VERSION ""

NS_ :

BS_:

BU_: APU BCU DCH DCL MCU TMS VIU WBS VIU1

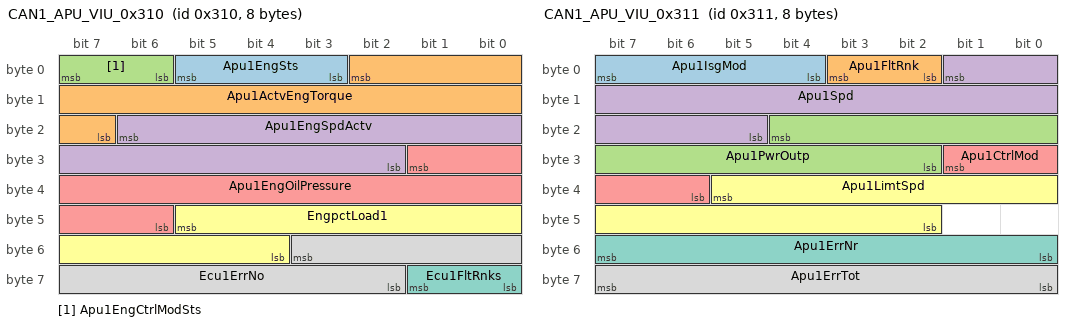
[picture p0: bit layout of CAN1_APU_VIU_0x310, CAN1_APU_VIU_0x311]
BO_ 784 CAN1_APU_VIU_0x310: 8 APU
 SG_ Apu1EngSts : 5|3@0+ (1,0) [0|7] ""  VIU
 SG_ Apu1ActvEngTorque : 2|12@0+ (1,-1250) [-1250|1250] "Nm"  VIU
 SG_ Apu1EngCtrlModSts : 7|2@0+ (1,0) [0|3] ""  VIU
 SG_ Apu1EngSpdActv : 22|13@0+ (1,0) [0|8000] "rpm"  VIU
 SG_ Apu1EngOilPressure : 25|12@0+ (0.055,0) [0|220] "mPa"  VIU
 SG_ EngpctLoad1 : 45|10@0+ (0.1,0) [0|100] "%"  VIU
 SG_ Ecu1FltRnks : 57|2@0+ (1,0) [0|3] ""  VIU
 SG_ Ecu1ErrNo : 51|10@0+ (1,0) [0|1000] ""  VIU

BO_ 785 CAN1_APU_VIU_0x311: 8 APU
 SG_ Apu1IsgMod : 7|4@0+ (1,0) [0|15] ""  VIU
 SG_ Apu1FltRnk : 3|2@0+ (1,0) [0|3] ""  VIU
 SG_ Apu1PwrOutp : 20|11@0+ (0.1,-150) [-150|50] "kW"  VIU
 SG_ Apu1Spd : 1|13@0+ (5,-15000) [-15000|15000] "rpm"  VIU
 SG_ Apu1CtrlMod : 25|4@0+ (1,0) [0|15] ""  VIU
 SG_ Apu1LimtSpd : 37|12@0+ (5,-8000) [-8000|8000] "rpm"  VIU
 SG_ Apu1ErrNr : 55|8@0+ (1,0) [0|255] ""  VIU
 SG_ Apu1ErrTot : 63|8@0+ (1,0) [0|255] ""  VIU

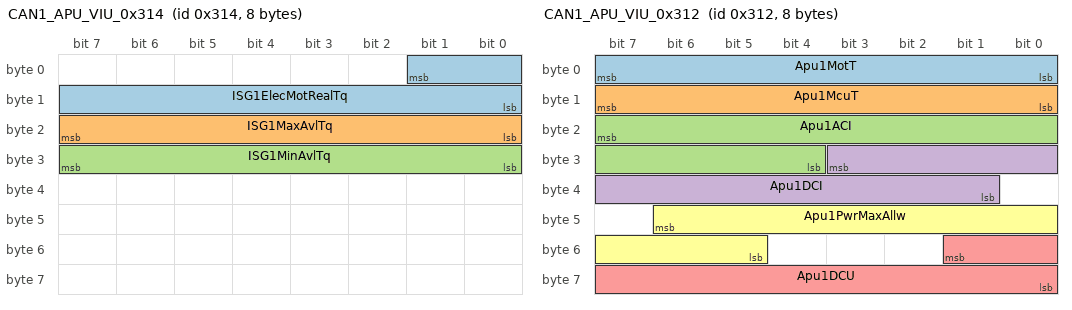
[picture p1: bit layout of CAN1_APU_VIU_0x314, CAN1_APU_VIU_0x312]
BO_ 788 CAN1_APU_VIU_0x314: 8 APU
 SG_ ISG1ElecMotRealTq : 1|10@0+ (1,-250) [-250|250] "Nm"  VIU
 SG_ ISG1MaxAvlTq : 23|8@0+ (1,0) [0|250] "Nm"  VIU
 SG_ ISG1MinAvlTq : 31|8@0+ (1,-250) [-250|0] "Nm"  VIU

BO_ 786 CAN1_APU_VIU_0x312: 8 APU
 SG_ Apu1MotT : 7|8@0+ (1,-50) [-50|200] "℃"  VIU
 SG_ Apu1McuT : 15|8@0+ (1,-50) [-50|200] "℃"  VIU
 SG_ Apu1ACI : 23|12@0+ (1,0) [0|1500] "A"  VIU
 SG_ Apu1DCI : 27|11@0+ (1,-1000) [-1000|1000] "A"  VIU
 SG_ Apu1DCU : 49|10@0+ (1,0) [0|1000] "V"  VIU
 SG_ Apu1PwrMaxAllw : 46|10@0+ (1,0) [0|1000] "kW"  VIU

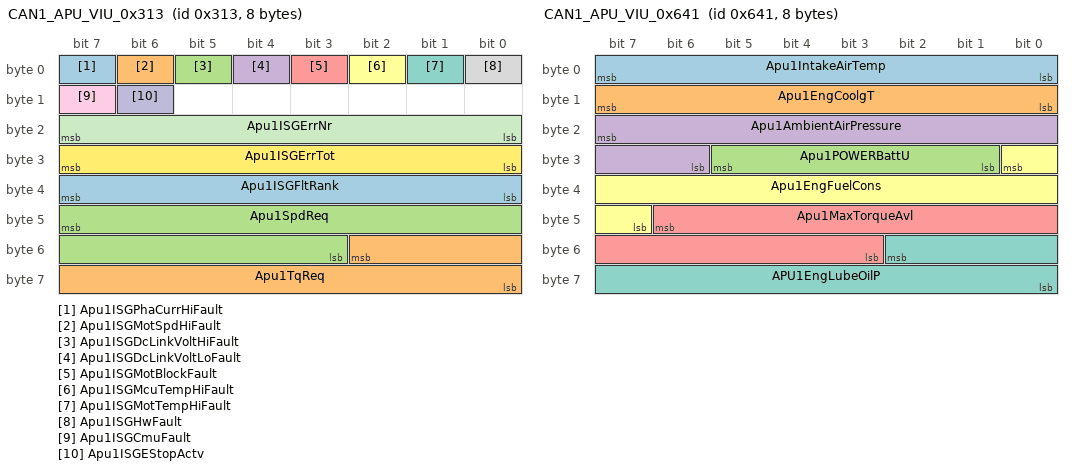
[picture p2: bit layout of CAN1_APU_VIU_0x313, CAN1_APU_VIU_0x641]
BO_ 787 CAN1_APU_VIU_0x313: 8 APU
 SG_ Apu1ISGPhaCurrHiFault : 7|1@0+ (1,0) [0|1] ""  VIU
 SG_ Apu1ISGMotSpdHiFault : 6|1@0+ (1,0) [0|1] ""  VIU
 SG_ Apu1ISGDcLinkVoltHiFault : 5|1@0+ (1,0) [0|1] ""  VIU
 SG_ Apu1ISGDcLinkVoltLoFault : 4|1@0+ (1,0) [0|1] ""  VIU
 SG_ Apu1ISGMotBlockFault : 3|1@0+ (1,0) [0|1] ""  VIU
 SG_ Apu1ISGMcuTempHiFault : 2|1@0+ (1,0) [0|1] ""  VIU
 SG_ Apu1ISGMotTempHiFault : 1|1@0+ (1,0) [0|1] ""  VIU
 SG_ Apu1ISGHwFault : 0|1@0+ (1,0) [0|1] ""  VIU
 SG_ Apu1ISGCmuFault : 15|1@0+ (1,0) [0|1] ""  VIU
 SG_ Apu1ISGEStopActv : 14|1@0+ (1,0) [0|1] ""  VIU
 SG_ Apu1ISGErrNr : 23|8@0+ (1,0) [0|255] ""  VIU
 SG_ Apu1ISGErrTot : 31|8@0+ (1,0) [0|255] ""  VIU
 SG_ Apu1ISGFltRank : 39|8@0+ (1,0) [0|255] ""  VIU
 SG_ Apu1TqReq : 50|11@0+ (0.5,-500) [-500|500] "Nm"  VIU
 SG_ Apu1SpdReq : 47|13@0+ (5,0) [0|10000] "rpm"  VIU

BO_ 1601 CAN1_APU_VIU_0x641: 8 APU
 SG_ Apu1IntakeAirTemp : 7|8@0+ (1,-40) [-40|210] "℃"  VIU
 SG_ Apu1EngCoolgT : 15|8@0+ (1,-40) [-40|210] "℃"  VIU
 SG_ Apu1POWERBattU : 29|5@0+ (1,0) [0|30] "V"  VIU
 SG_ Apu1AmbientAirPressure : 23|10@0+ (1,0) [0|1000] "kPa"  VIU
 SG_ Apu1MaxTorqueAvl : 46|12@0+ (1,-1250) [-1250|1250] "Nm"  VIU
 SG_ Apu1EngFuelCons : 24|10@0+ (0.05,0) [0|51] "mL"  VIU
 SG_ APU1EngLubeOilP : 50|11@0+ (1,0) [0|1000] "kPa"  VIU

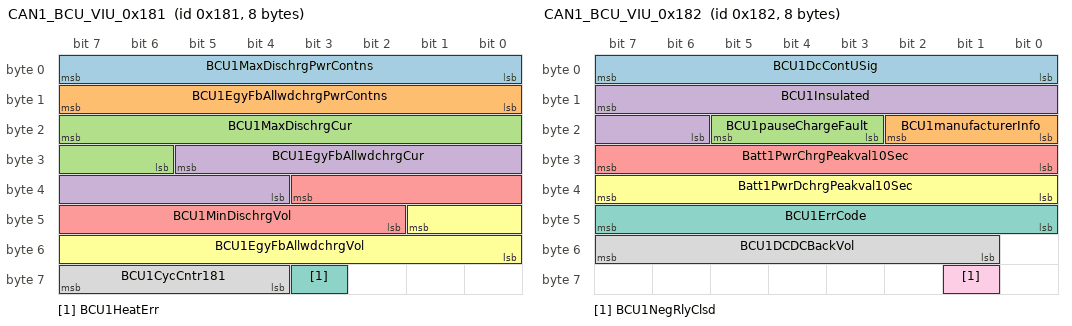
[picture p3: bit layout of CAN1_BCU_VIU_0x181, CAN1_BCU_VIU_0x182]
BO_ 385 CAN1_BCU_VIU_0x181: 8 BCU
 SG_ BCU1MaxDischrgPwrContns : 7|8@0+ (0.5,0) [0|125] "kW"  VIU
 SG_ BCU1EgyFbAllwdchrgPwrContns : 15|8@0+ (0.5,0) [0|125] "kW"  VIU
 SG_ BCU1MaxDischrgCur : 23|10@0+ (1,0) [0|500] "kW"  VIU
 SG_ BCU1EgyFbAllwdchrgCur : 29|10@0+ (1,0) [0|500] "A"  VIU
 SG_ BCU1MinDischrgVol : 35|10@0+ (1,0) [0|800] "V"  VIU
 SG_ BCU1EgyFbAllwdchrgVol : 41|10@0+ (1,0) [0|800] "V"  VIU
 SG_ BCU1HeatErr : 59|1@0+ (1,0) [0|1] ""  VIU
 SG_ BCU1CycCntr181 : 63|4@0+ (1,0) [0|15] "V"  VIU

BO_ 386 CAN1_BCU_VIU_0x182: 8 BCU
 SG_ BCU1DcContUSig : 7|8@0+ (0.1,0) [0|20] "V"  VIU
 SG_ BCU1manufacturerInfo : 18|3@0+ (1,0) [0|7] ""  VIU
 SG_ BCU1pauseChargeFault : 21|3@0+ (1,0) [0|7] ""  VIU
 SG_ BCU1Insulated : 15|10@0+ (1,0) [0|1000] "kΩ"  VIU
 SG_ Batt1PwrChrgPeakval10Sec : 31|8@0+ (0.5,0) [0|125] "kW"  VIU
 SG_ Batt1PwrDchrgPeakval10Sec : 39|8@0+ (0.5,0) [0|125] "kW"  VIU
 SG_ BCU1ErrCode : 47|8@0+ (1,0) [0|255] ""  VIU
 SG_ BCU1DCDCBackVol : 55|7@0+ (5,0) [0|635] "V"  VIU
 SG_ BCU1NegRlyClsd : 57|1@0+ (1,0) [0|1] ""  VIU

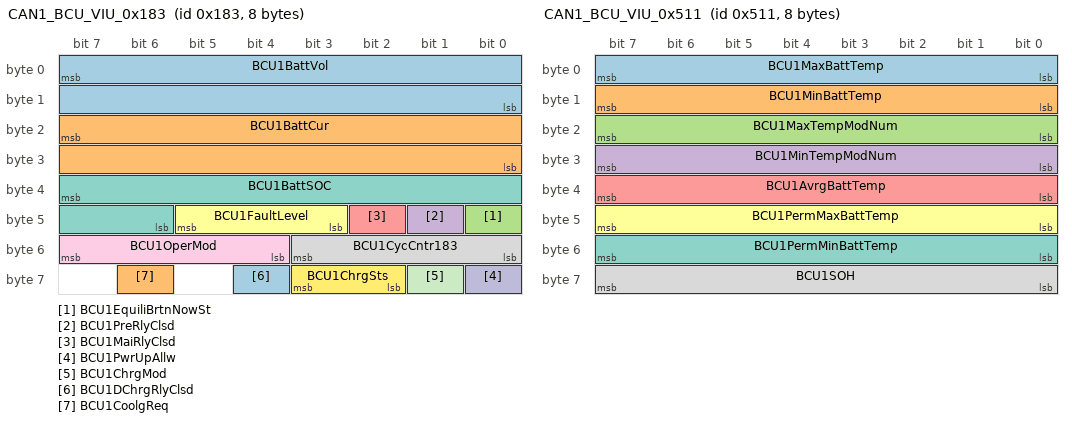
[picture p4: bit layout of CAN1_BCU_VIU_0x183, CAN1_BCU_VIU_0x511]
BO_ 387 CAN1_BCU_VIU_0x183: 8 BCU
 SG_ BCU1BattVol : 7|16@0+ (0.1,0) [0|800] "V"  VIU
 SG_ BCU1BattCur : 23|16@0+ (0.1,-500) [-500|500] "A"  VIU
 SG_ BCU1EquiliBrtnNowSt : 40|1@0+ (1,0) [0|1] ""  VIU
 SG_ BCU1PreRlyClsd : 41|1@0+ (1,0) [0|1] ""  VIU
 SG_ BCU1MaiRlyClsd : 42|1@0+ (1,0) [0|1] ""  VIU
 SG_ BCU1FaultLevel : 45|3@0+ (1,0) [0|4] ""  VIU
 SG_ BCU1BattSOC : 39|10@0+ (0.1,0) [0|100] "%"  VIU
 SG_ BCU1CycCntr183 : 51|4@0+ (1,0) [0|15] ""  VIU
 SG_ BCU1OperMod : 55|4@0+ (1,0) [0|15] ""  VIU
 SG_ BCU1PwrUpAllw : 56|1@0+ (1,0) [0|1] ""  VIU
 SG_ BCU1ChrgMod : 57|1@0+ (1,0) [0|1] ""  VIU
 SG_ BCU1ChrgSts : 59|2@0+ (1,0) [0|3] ""  VIU
 SG_ BCU1DChrgRlyClsd : 60|1@0+ (1,0) [0|1] ""  VIU
 SG_ BCU1CoolgReq : 62|1@0+ (1,0) [0|1] ""  VIU

BO_ 1297 CAN1_BCU_VIU_0x511: 8 BCU
 SG_ BCU1MaxBattTemp : 7|8@0+ (1,-40) [-40|125] "℃"  VIU
 SG_ BCU1MinBattTemp : 15|8@0+ (1,-40) [-40|125] "℃"  VIU
 SG_ BCU1MaxTempModNum : 23|8@0+ (1,0) [1|120] ""  VIU
 SG_ BCU1MinTempModNum : 31|8@0+ (1,0) [1|120] ""  VIU
 SG_ BCU1AvrgBattTemp : 39|8@0+ (1,-40) [-40|125] "℃"  VIU
 SG_ BCU1PermMaxBattTemp : 47|8@0+ (1,-40) [-40|125] "℃"  VIU
 SG_ BCU1PermMinBattTemp : 55|8@0+ (1,-40) [-40|125] "℃"  VIU
 SG_ BCU1SOH : 63|8@0+ (1,0) [0|100] "%"  VIU

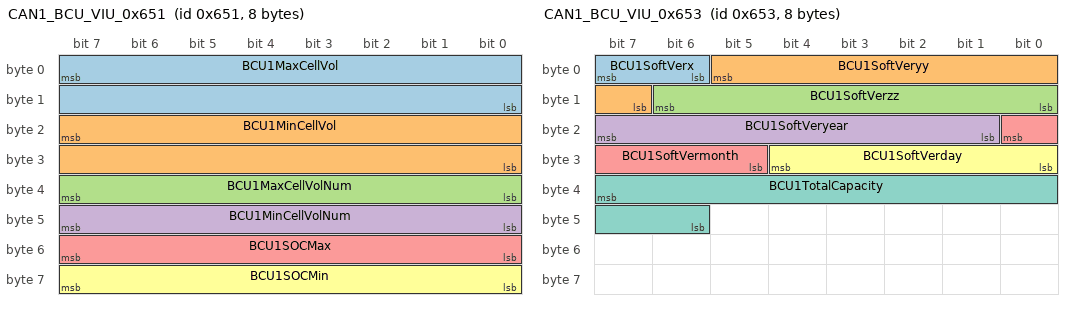
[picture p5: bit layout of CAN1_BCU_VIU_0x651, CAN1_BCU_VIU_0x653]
BO_ 1617 CAN1_BCU_VIU_0x651: 8 BCU
 SG_ BCU1MaxCellVol : 7|16@0+ (0.001,0) [0|10.001] "V"  VIU
 SG_ BCU1MinCellVol : 23|16@0+ (0.001,0) [0|10.001] "V"  VIU
 SG_ BCU1MaxCellVolNum : 39|8@0+ (1,0) [1|110] ""  VIU
 SG_ BCU1MinCellVolNum : 47|8@0+ (1,0) [1|110] ""  VIU
 SG_ BCU1SOCMax : 55|8@0+ (1,0) [0|100] "%"  VIU
 SG_ BCU1SOCMin : 63|8@0+ (1,0) [0|100] "%"  VIU

BO_ 1618 CAN1_BCU_VIU_0x652: 8 BCU
 SG_ BCU1CellDeltaVolRank2 : 0|1@0+ (1,0) [0|1] ""  VIU
 SG_ BCU1CellDeltaVolRank1 : 1|1@0+ (1,0) [0|1] ""  VIU
 SG_ BCU1CellUnderVolRank3 : 2|1@0+ (1,0) [0|1] ""  VIU
 SG_ BCU1CellUnderVolRank2 : 3|1@0+ (1,0) [0|1] ""  VIU
 SG_ BCU1CellUnderVolRank1 : 4|1@0+ (1,0) [0|1] ""  VIU
 SG_ BCU1CellOverVolRank3 : 5|1@0+ (1,0) [0|1] ""  VIU
 SG_ BCU1CellOverVolRank2 : 6|1@0+ (1,0) [0|1] ""  VIU
 SG_ BCU1CellOverVolRank1 : 7|1@0+ (1,0) [0|1] ""  VIU
 SG_ BCU1OverCurtChrgRank3 : 8|1@0+ (1,0) [0|1] ""  VIU
 SG_ BCU1OverCurtChrgRank2 : 9|1@0+ (1,0) [0|1] ""  VIU
 SG_ BCU1OverCurtChrgRank1 : 10|1@0+ (1,0) [0|1] ""  VIU
 SG_ BCU1PrechrgFailErr : 11|1@0+ (1,0) [0|1] ""  VIU
 SG_ BCU1DCRlyPAdhErr : 12|1@0+ (1,0) [0|1] ""  VIU
 SG_ BCU1MaiRlyPAdhErr : 13|1@0+ (1,0) [0|1] ""  VIU
 SG_ BCU1MaiRlyNAdhErr : 14|1@0+ (1,0) [0|1] ""  VIU
 SG_ BCU1CC2Err : 15|1@0+ (1,0) [0|1] ""  VIU
 SG_ BCU1OverPeakCurtDischrgRank2 : 16|1@0+ (1,0) [0|1] ""  VIU
 SG_ BCU1OverPeakCurtDischrgRank1 : 17|1@0+ (1,0) [0|1] ""  VIU
 SG_ BCU1OverCurtDischrgRank3 : 18|1@0+ (1,0) [0|1] ""  VIU
 SG_ BCU1OverCurtDischrgRank2 : 19|1@0+ (1,0) [0|1] ""  VIU
 SG_ BCU1OverCurtDischrgRank1 : 20|1@0+ (1,0) [0|1] ""  VIU
 SG_ BCU1OverPeakCurtChrgRank3 : 21|1@0+ (1,0) [0|1] ""  VIU
 SG_ BCU1OverPeakCurtChrgRank2 : 22|1@0+ (1,0) [0|1] ""  VIU
 SG_ BCU1OverPeakCurtChrgRank1 : 23|1@0+ (1,0) [0|1] ""  VIU
 SG_ BCU1BattUnderTempRank2 : 24|1@0+ (1,0) [0|1] ""  VIU
 SG_ BCU1BattOverTempRank4 : 25|1@0+ (1,0) [0|1] ""  VIU
 SG_ BCU1BattOverTempRank3 : 26|1@0+ (1,0) [0|1] ""  VIU
 SG_ BCU1BattOverTempRank2 : 27|1@0+ (1,0) [0|1] ""  VIU
 SG_ BCU1ChrgErr : 28|1@0+ (1,0) [0|1] ""  VIU
 SG_ BCU1BattSOHLo : 29|1@0+ (1,0) [0|1] ""  VIU
 SG_ BCU1TotVolRatiErr : 30|1@0+ (1,0) [0|1] ""  VIU
 SG_ BCU1OverPeakCurtDischrgRank3 : 31|1@0+ (1,0) [0|1] ""  VIU
 SG_ BCU1BattOverURank2 : 32|1@0+ (1,0) [0|1] ""  VIU
 SG_ BCU1BattOverVolRank1 : 33|1@0+ (1,0) [0|1] ""  VIU
 SG_ BCU1InsuFlt4 : 34|1@0+ (1,0) [0|1] ""  VIU
 SG_ BCU1InsuFlt2 : 35|1@0+ (1,0) [0|1] ""  VIU
 SG_ BCU1HVILErr : 36|1@0+ (1,0) [0|1] ""  VIU
 SG_ BCU1DeltaTempRank3 : 37|1@0+ (1,0) [0|1] ""  VIU
 SG_ BCU1DeltaTempRank2 : 38|1@0+ (1,0) [0|1] ""  VIU
 SG_ BCU1BattUnderTempRank3 : 39|1@0+ (1,0) [0|1] ""  VIU
 SG_ BCU1SOCHopErr : 40|1@0+ (1,0) [0|1] ""  VIU
 SG_ BCU1SOCcalcErr : 41|1@0+ (1,0) [0|1] ""  VIU
 SG_ BCU1BattOverPwr : 42|1@0+ (1,0) [0|1] ""  VIU
 SG_ BCU1DCchrgInsuFlt : 43|1@0+ (1,0) [0|1] ""  VIU
 SG_ BCU1BattUnderVolRank3 : 44|1@0+ (1,0) [0|1] ""  VIU
 SG_ BCU1BattUnderVolRank2 : 45|1@0+ (1,0) [0|1] ""  VIU
 SG_ BCU1BattUnderURank1 : 46|1@0+ (1,0) [0|1] ""  VIU
 SG_ BCU1BattOverURank3 : 47|1@0+ (1,0) [0|1] ""  VIU
 SG_ BCU1TotVolSnsrElecErr : 48|1@0+ (1,0) [0|1] ""  VIU
 SG_ BCU1SlaveCALFAULT : 49|1@0+ (1,0) [0|1] ""  VIU
 SG_ BCU1InlrCANErr : 50|1@0+ (1,0) [0|1] ""  VIU
 SG_ BCU1ChrgCANErr : 51|1@0+ (1,0) [0|1] ""  VIU
 SG_ BCU1VehCANErr : 52|1@0+ (1,0) [0|1] ""  VIU
 SG_ BCU1BlcErr : 53|1@0+ (1,0) [0|1] ""  VIU
 SG_ BCU1ChargerOverTemp3 : 54|1@0+ (1,0) [0|1] ""  VIU
 SG_ BCU1ChargerOverTemp2 : 55|1@0+ (1,0) [0|1] ""  VIU
 SG_ BCU1DCchrgTemErr : 57|1@0+ (1,0) [0|1] ""  VIU
 SG_ BCU1EEpErr : 58|1@0+ (1,0) [0|1] ""  VIU
 SG_ BCU1WatchDogErr : 59|1@0+ (1,0) [0|1] ""  VIU
 SG_ BCU1ROMCheckErr : 60|1@0+ (1,0) [0|1] ""  VIU
 SG_ BCU1RAMCheckErr : 61|1@0+ (1,0) [0|1] ""  VIU
 SG_ BCU1TempSnsrElecErr : 62|1@0+ (1,0) [0|1] ""  VIU
 SG_ BCU1TotCurtSnsrElecErr : 63|1@0+ (1,0) [0|1] ""  VIU

BO_ 1619 CAN1_BCU_VIU_0x653: 8 BCU
 SG_ BCU1SoftVerx : 7|2@0+ (1,0) [0|3] ""  VIU
 SG_ BCU1SoftVeryy : 5|7@0+ (1,0) [0|99] ""  VIU
 SG_ BCU1SoftVerzz : 14|7@0+ (1,0) [0|99] ""  VIU
 SG_ BCU1SoftVeryear : 23|7@0+ (1,2000) [2000|2099] ""  VIU
 SG_ BCU1SoftVermonth : 16|4@0+ (1,0) [1|12] ""  VIU
 SG_ BCU1SoftVerday : 28|5@0+ (1,0) [1|31] ""  VIU
 SG_ BCU1TotalCapacity : 39|10@0+ (0.1,0) [0|100] "Ah"  VIU

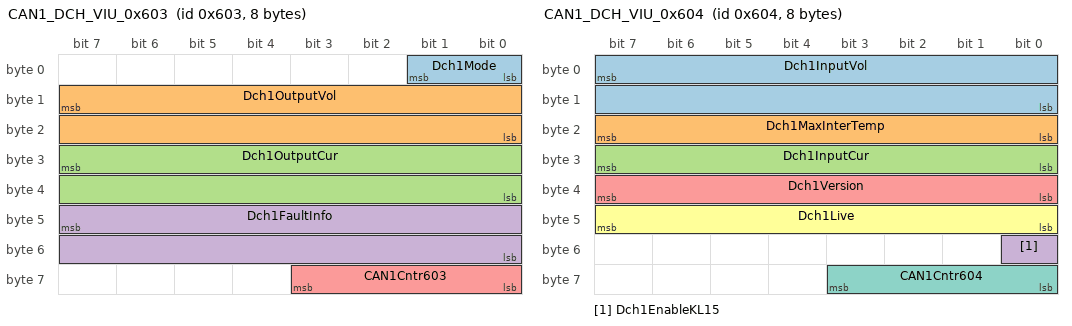
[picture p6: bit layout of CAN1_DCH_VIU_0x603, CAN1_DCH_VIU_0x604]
BO_ 1539 CAN1_DCH_VIU_0x603: 8 DCH
 SG_ Dch1Mode : 1|2@0+ (1,0) [0|3] ""  VIU
 SG_ Dch1OutputVol : 15|16@0+ (0.1,0) [0|6553.5] "V"  VIU
 SG_ Dch1OutputCur : 31|16@0+ (0.1,0) [0|6553.5] "A"  VIU
 SG_ Dch1FaultInfo : 47|16@0+ (1,0) [0|65535] ""  VIU
 SG_ CAN1Cntr603 : 59|4@0+ (1,0) [0|15] ""  VIU

BO_ 1540 CAN1_DCH_VIU_0x604: 8 DCH
 SG_ Dch1InputVol : 7|16@0+ (0.1,0) [0|6553.5] "V"  VIU
 SG_ Dch1MaxInterTemp : 23|8@0+ (1,-40) [-40|215] "℃"  VIU
 SG_ Dch1InputCur : 31|8@0+ (0.1,0) [0|25.5] "A"  VIU
 SG_ Dch1EnableKL15 : 48|1@0+ (1,0) [0|1] ""  VIU
 SG_ Dch1Version : 39|8@0+ (1,0) [0|255] ""  VIU
 SG_ Dch1Live : 47|8@0+ (1,0) [0|255] ""  VIU
 SG_ CAN1Cntr604 : 59|4@0+ (1,0) [0|15] ""  VIU

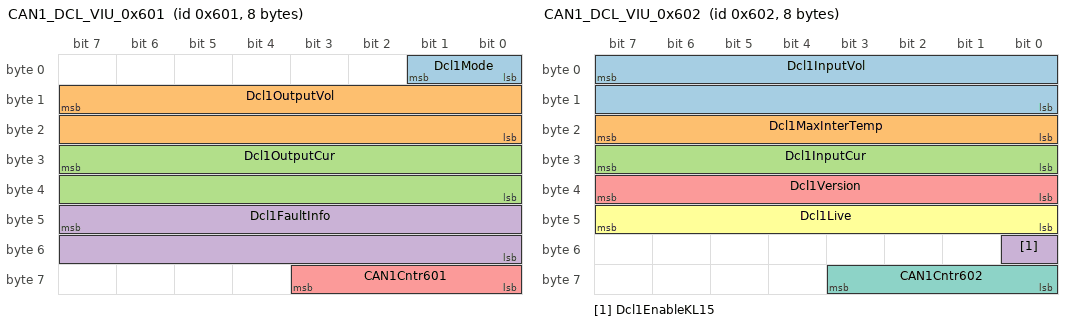
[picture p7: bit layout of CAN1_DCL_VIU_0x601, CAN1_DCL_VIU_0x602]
BO_ 1537 CAN1_DCL_VIU_0x601: 8 DCL
 SG_ Dcl1Mode : 1|2@0+ (1,0) [0|3] ""  VIU
 SG_ Dcl1OutputVol : 15|16@0+ (0.1,0) [0|6553.5] "V"  VIU
 SG_ Dcl1OutputCur : 31|16@0+ (0.1,0) [0|6553.5] "A"  VIU
 SG_ Dcl1FaultInfo : 47|16@0+ (1,0) [0|65535] ""  VIU
 SG_ CAN1Cntr601 : 59|4@0+ (1,0) [0|15] ""  VIU

BO_ 1538 CAN1_DCL_VIU_0x602: 8 DCL
 SG_ Dcl1InputVol : 7|16@0+ (0.1,0) [0|6553.5] "V"  VIU
 SG_ Dcl1MaxInterTemp : 23|8@0+ (1,-40) [-40|215] "℃"  VIU
 SG_ Dcl1InputCur : 31|8@0+ (0.1,0) [0|25.5] "A"  VIU
 SG_ Dcl1EnableKL15 : 48|1@0+ (1,0) [0|1] ""  VIU
 SG_ Dcl1Version : 39|8@0+ (1,0) [0|255] ""  VIU
 SG_ Dcl1Live : 47|8@0+ (1,0) [0|255] ""  VIU
 SG_ CAN1Cntr602 : 59|4@0+ (1,0) [0|15] ""  VIU

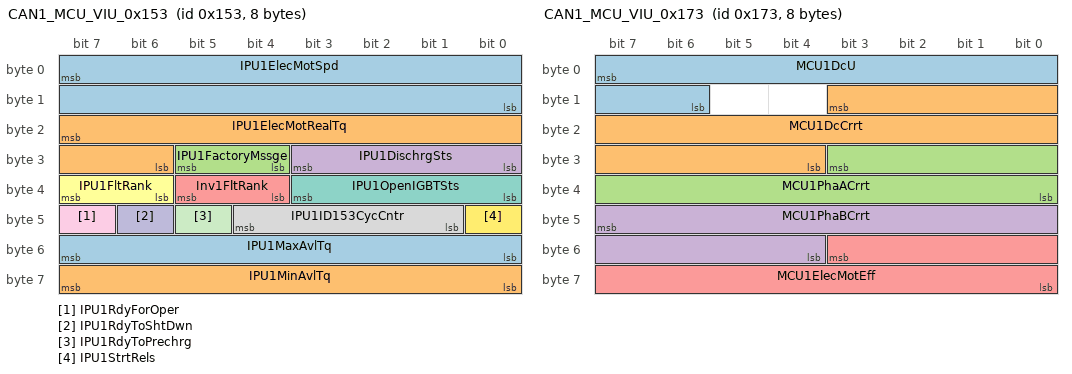
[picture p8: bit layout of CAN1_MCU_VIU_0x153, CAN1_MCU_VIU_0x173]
BO_ 339 CAN1_MCU_VIU_0x153: 8 MCU
 SG_ IPU1ElecMotSpd : 7|16@0+ (1,-25000) [-25000|25000] "rpm"  VIU
 SG_ IPU1ElecMotRealTq : 23|10@0+ (1,-250) [-250|250] "Nm"  VIU
 SG_ IPU1FactoryMssge : 29|2@0+ (1,0) [0|3] ""  VIU
 SG_ IPU1DischrgSts : 27|4@0+ (1,0) [0|15] ""  VIU
 SG_ Inv1FltRank : 37|2@0+ (1,0) [0|3] ""  VIU
 SG_ IPU1FltRank : 39|2@0+ (1,0) [0|3] ""  VIU
 SG_ IPU1OpenIGBTSts : 35|4@0+ (1,0) [0|15] ""  VIU
 SG_ IPU1ID153CycCntr : 44|4@0+ (1,0) [0|15] ""  VIU
 SG_ IPU1RdyForOper : 47|1@0+ (1,0) [0|1] ""  VIU
 SG_ IPU1RdyToShtDwn : 46|1@0+ (1,0) [0|1] ""  VIU
 SG_ IPU1RdyToPrechrg : 45|1@0+ (1,0) [0|1] ""  VIU
 SG_ IPU1StrtRels : 40|1@0+ (1,0) [0|1] ""  VIU
 SG_ IPU1MaxAvlTq : 55|8@0+ (1,0) [0|250] "Nm"  VIU
 SG_ IPU1MinAvlTq : 63|8@0+ (1,-250) [-250|0] "Nm"  VIU

BO_ 371 CAN1_MCU_VIU_0x173: 8 MCU
 SG_ MCU1DcU : 7|10@0+ (1,0) [0|500] "V"  VIU
 SG_ MCU1DcCrrt : 11|16@0+ (0.1,-500) [-500|500] "A"  VIU
 SG_ MCU1PhaACrrt : 27|12@0+ (1,-800) [-800|800] "A"  VIU
 SG_ MCU1PhaBCrrt : 47|12@0+ (1,-800) [-800|800] "A"  VIU
 SG_ MCU1ElecMotEff : 51|12@0+ (0.1,0) [0|100] "%"  VIU

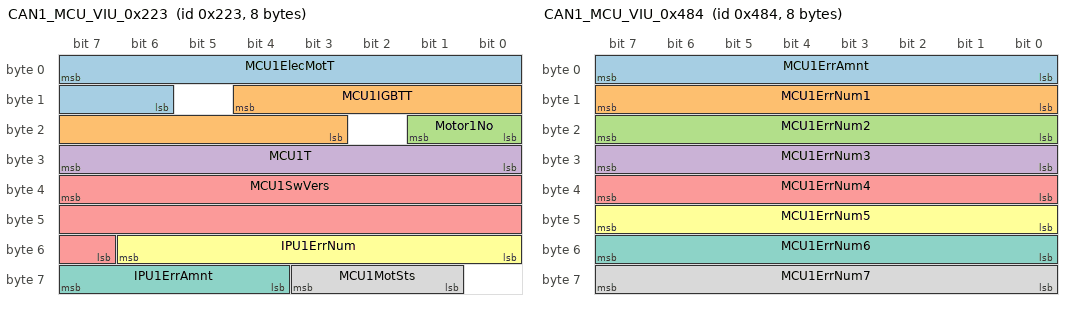
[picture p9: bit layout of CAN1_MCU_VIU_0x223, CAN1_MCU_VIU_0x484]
BO_ 547 CAN1_MCU_VIU_0x223: 8 MCU
 SG_ MCU1ElecMotT : 7|10@0+ (1,-50) [-50|200] "°C"  VIU
 SG_ MCU1IGBTT : 12|10@0+ (1,-50) [-50|200] "°C"  VIU
 SG_ Motor1No : 17|2@0+ (1,0) [0|3] ""  VIU
 SG_ MCU1T : 31|8@0+ (1,-50) [-50|150] "°C"  VIU
 SG_ MCU1SwVers : 39|17@0+ (1,0) [0|130000] ""  VIU
 SG_ IPU1ErrNum : 54|7@0+ (1,0) [0|127] ""  VIU
 SG_ IPU1ErrAmnt : 63|4@0+ (1,0) [0|15] ""  VIU
 SG_ MCU1MotSts : 59|3@0+ (1,0) [0|7] ""  VIU

BO_ 1155 CAN1_MCU_VIU_0x483: 8 MCU
 SG_ CurrentLimitErr1 : 7|1@0+ (1,0) [0|1] ""  VIU
 SG_ MCU1IGBTOverTL : 6|1@0+ (1,0) [0|1] ""  VIU
 SG_ MCU1IGBTOverTH : 5|1@0+ (1,0) [0|1] ""  VIU
 SG_ MCU1ElecMotOverTL : 4|1@0+ (1,0) [0|1] ""  VIU
 SG_ MCU1ElecMotOverTH : 3|1@0+ (1,0) [0|1] ""  VIU
 SG_ MCU1PwrOutpModFlt : 2|1@0+ (1,0) [0|1] ""  VIU
 SG_ MCU1HardwareOverCurrent : 1|1@0+ (1,0) [0|1] ""  VIU
 SG_ MCU1ElecMotOverSpd : 0|1@0+ (1,0) [0|1] ""  VIU
 SG_ MCU1HiUUnderUL : 15|1@0+ (1,0) [0|1] ""  VIU
 SG_ MCU1HiUOverUL : 14|1@0+ (1,0) [0|1] ""  VIU
 SG_ MCU1CANComErr : 13|1@0+ (1,0) [0|1] ""  VIU
 SG_ MCU1DischrgErr : 12|1@0+ (1,0) [0|1] ""  VIU
 SG_ MCU1SoftwareOverCurrent : 11|1@0+ (1,0) [0|1] ""  VIU
 SG_ MCU1ElecMotReslvErr : 10|1@0+ (1,0) [0|1] ""  VIU
 SG_ MCU1ElecMotThreePhaBreakErr : 9|1@0+ (1,0) [0|1] ""  VIU
 SG_ MCU1HiUUnderUH : 8|1@0+ (1,0) [0|1] ""  VIU
 SG_ MCU1HiUOverUH : 23|1@0+ (1,0) [0|1] ""  VIU
 SG_ MCU1LowBatErr : 22|1@0+ (1,0) [0|1] ""  VIU
 SG_ MCU1FAULTDATASELF : 21|1@0+ (1,0) [0|1] ""  VIU
 SG_ MCU1FAULTUUPIGBT : 20|1@0+ (1,0) [0|1] ""  VIU
 SG_ MCU1FAULTUDOWNIGBT : 19|1@0+ (1,0) [0|1] ""  VIU
 SG_ MCU1FAULTVUPIGBT : 18|1@0+ (1,0) [0|1] ""  VIU
 SG_ MCU1FAULTVDOWNIGBT : 17|1@0+ (1,0) [0|1] ""  VIU
 SG_ MCU1HardwareOverU : 16|1@0+ (1,0) [0|1] ""  VIU
 SG_ MCU1FAULTWUPIGBT : 31|1@0+ (1,0) [0|1] ""  VIU
 SG_ MCU1FAULTWDOWNIGBT : 30|1@0+ (1,0) [0|1] ""  VIU
 SG_ MCU1LowBatWarning : 29|1@0+ (1,0) [0|1] ""  VIU
 SG_ MCU1ElecMotOverSpdWarning : 28|1@0+ (1,0) [0|1] ""  VIU
 SG_ MCU1IGBTTSnsrShoCircGnd : 27|1@0+ (1,0) [0|1] ""  VIU
 SG_ MCU1IGBTTSnsrShoCircVcc : 26|1@0+ (1,0) [0|1] ""  VIU
 SG_ MCU1OverLoadErr : 25|1@0+ (1,0) [0|1] ""  VIU
 SG_ MCU1OverLoadWraning : 24|1@0+ (1,0) [0|1] ""  VIU
 SG_ MCU1ElecMotTSnsrShoCircGnd : 39|1@0+ (1,0) [0|1] ""  VIU
 SG_ MCU1ElecMotStopTurnErr : 38|1@0+ (1,0) [0|1] ""  VIU
 SG_ MCU1ElecMotTSnsrOpenCirc : 37|1@0+ (1,0) [0|1] ""  VIU
 SG_ MCU1FAULTHUOC : 36|1@0+ (1,0) [0|1] ""  VIU
 SG_ MCU1FAULTHVOC : 35|1@0+ (1,0) [0|1] ""  VIU
 SG_ MCU1FAULTHWOC : 34|1@0+ (1,0) [0|1] ""  VIU
 SG_ MCU1CurrentDetectErr : 33|1@0+ (1,0) [0|1] ""  VIU
 SG_ MCU1TempErr : 32|1@0+ (1,0) [0|1] ""  VIU
 SG_ MCU1rDriverUV : 47|1@0+ (1,0) [0|1] ""  VIU
 SG_ MCU1PhaseShortCircuit : 46|1@0+ (1,0) [0|1] ""  VIU
 SG_ MCU1FastUV : 45|1@0+ (1,0) [0|1] ""  VIU
 SG_ MCU1alarmOTNTC : 44|1@0+ (1,0) [0|1] ""  VIU
 SG_ MCU1OTNTC : 43|1@0+ (1,0) [0|1] ""  VIU
 SG_ MCU1alarmOperateOrder : 42|1@0+ (1,0) [0|1] ""  VIU
 SG_ EEPROMErr1 : 41|1@0+ (1,0) [0|1] ""  VIU
 SG_ AngleDiffErr1 : 40|1@0+ (1,0) [0|1] ""  VIU
 SG_ MCU1alarmHighSpeedStop : 55|1@0+ (1,0) [0|1] ""  VIU
 SG_ MCU1alarmHighSpeedDir : 54|1@0+ (1,0) [0|1] ""  VIU
 SG_ MCU1alarmHighTorqueStop : 53|1@0+ (1,0) [0|1] ""  VIU
 SG_ MCU1Dev : 52|1@0+ (1,0) [0|1] ""  VIU
 SG_ errorCanBSend1 : 51|1@0+ (1,0) [0|1] ""  VIU
 SG_ errorCanBReceive1 : 50|1@0+ (1,0) [0|1] ""  VIU
 SG_ InterlockErr1 : 49|1@0+ (1,0) [0|1] ""  VIU
 SG_ PTCAdhesion1 : 48|1@0+ (1,0) [0|1] ""  VIU

BO_ 1156 CAN1_MCU_VIU_0x484: 8 MCU
 SG_ MCU1ErrAmnt : 7|8@0+ (1,0) [0|255] ""  VIU
 SG_ MCU1ErrNum1 : 15|8@0+ (1,0) [0|255] ""  VIU
 SG_ MCU1ErrNum2 : 23|8@0+ (1,0) [0|255] ""  VIU
 SG_ MCU1ErrNum3 : 31|8@0+ (1,0) [0|255] ""  VIU
 SG_ MCU1ErrNum4 : 39|8@0+ (1,0) [0|255] ""  VIU
 SG_ MCU1ErrNum5 : 47|8@0+ (1,0) [0|255] ""  VIU
 SG_ MCU1ErrNum6 : 55|8@0+ (1,0) [0|255] ""  VIU
 SG_ MCU1ErrNum7 : 63|8@0+ (1,0) [0|255] ""  VIU

BO_ 257 CAN1_VIU_VIU1_0x101: 8 VIU
 SG_ PtWhlLocnS : 12|2@0+ (1,0) [0|3] ""  VIU1
 SG_ PtWhlCompanionBattAvlS : 57|1@0+ (1,0) [0|1] ""  VIU1
 SG_ PtWhlTypS : 49|2@0+ (1,0) [0|3] ""  VIU1
 SG_ VcuHvActvS : 14|1@0+ (1,0) [0|1] ""  VIU1
 SG_ VcuLvActvS : 15|1@0+ (1,0) [0|1] ""  VIU1
 SG_ VcuPwrSysStsNrS : 31|8@0+ (1,0) [0|1] ""  VIU1
 SG_ VCUApuPwrReqS : 10|11@0+ (0.1,-150) [-150|50] "kW"  VIU1
 SG_ VCUFuQntyS : 7|8@0+ (1,0) [0|100] "%"  VIU1
 SG_ VcuBcuFltRankS : 36|3@0+ (1,0) [0|7] ""  VIU1
 SG_ BcuCanStS : 38|1@0+ (1,0) [0|1] ""  VIU1
 SG_ VcuBcuSocS : 33|10@0+ (0.1,0) [0|100] "%"  VIU1
 SG_ EpbCtrlStsFbS : 53|4@0+ (1,0) [0|15] ""  VIU1
 SG_ VcuBcuPwrUpAllwS : 55|1@0+ (1,0) [0|1] ""  VIU1
 SG_ VcuBcuChrgModS : 56|1@0+ (1,0) [0|1] ""  VIU1
 SG_ VcuBcuChrgStsS : 59|2@0+ (1,0) [0|3] ""  VIU1
 SG_ VcuBcupauseChargeFaultS : 62|3@0+ (1,0) [0|7] ""  VIU1
 SG_ ErrChrgInhbReqS : 13|1@0+ (1,0) [0|1] ""  VIU1
 SG_ ErrLvUpInhbS : 37|1@0+ (1,0) [0|1] ""  VIU1
 SG_ ErrLvPwrDwnReqS : 39|1@0+ (1,0) [0|1] ""  VIU1

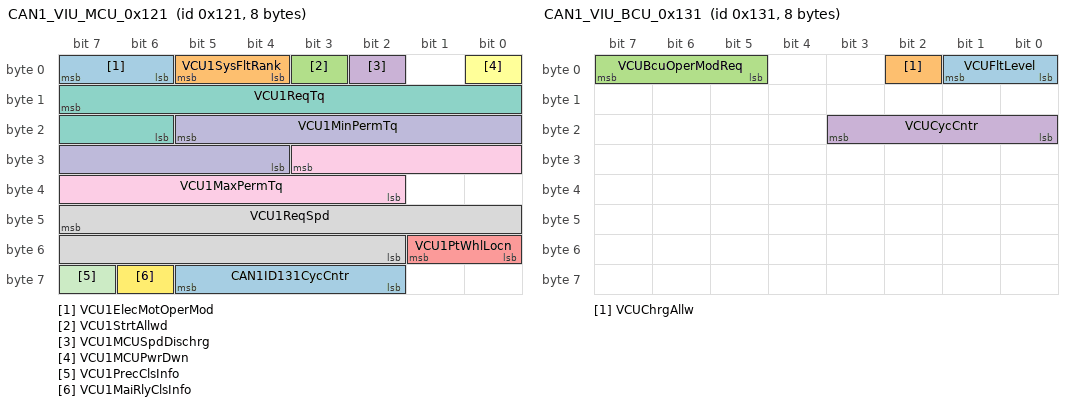
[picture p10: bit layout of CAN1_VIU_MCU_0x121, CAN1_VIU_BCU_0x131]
BO_ 289 CAN1_VIU_MCU_0x121: 8 VIU
 SG_ VCU1ElecMotOperMod : 7|2@0+ (1,0) [0|3] ""  MCU
 SG_ VCU1SysFltRank : 5|2@0+ (1,0) [0|3] ""  MCU
 SG_ VCU1StrtAllwd : 3|1@0+ (1,0) [0|1] ""  MCU
 SG_ VCU1MCUSpdDischrg : 2|1@0+ (1,0) [0|1] ""  MCU
 SG_ VCU1PtWhlLocn : 49|2@0+ (1,0) [0|3] ""  MCU
 SG_ VCU1MCUPwrDwn : 0|1@0+ (1,0) [0|1] ""  MCU
 SG_ VCU1ReqTq : 15|10@0+ (1,-300) [-300|300] "Nm"  MCU
 SG_ VCU1ReqSpd : 47|14@0+ (5,-10000) [-10000|10000] "rpm"  MCU
 SG_ VCU1MaxPermTq : 27|10@0+ (1,-250) [-250|250] "Nm"  MCU
 SG_ VCU1MinPermTq : 21|10@0+ (1,-250) [-250|250] "Nm"  MCU
 SG_ VCU1PrecClsInfo : 63|1@0+ (1,0) [0|1] ""  MCU
 SG_ VCU1MaiRlyClsInfo : 62|1@0+ (1,0) [0|1] ""  MCU
 SG_ CAN1ID131CycCntr : 61|4@0+ (1,0) [0|14] ""  MCU

BO_ 305 CAN1_VIU_BCU_0x131: 8 VIU
 SG_ VCUFltLevel : 1|2@0+ (1,0) [0|3] ""  BCU
 SG_ VCUChrgAllw : 2|1@0+ (1,0) [0|1] ""  BCU
 SG_ VCUBcuOperModReq : 7|3@0+ (1,0) [0|7] ""  BCU
 SG_ VCUCycCntr : 19|4@0+ (1,0) [0|14] ""  BCU

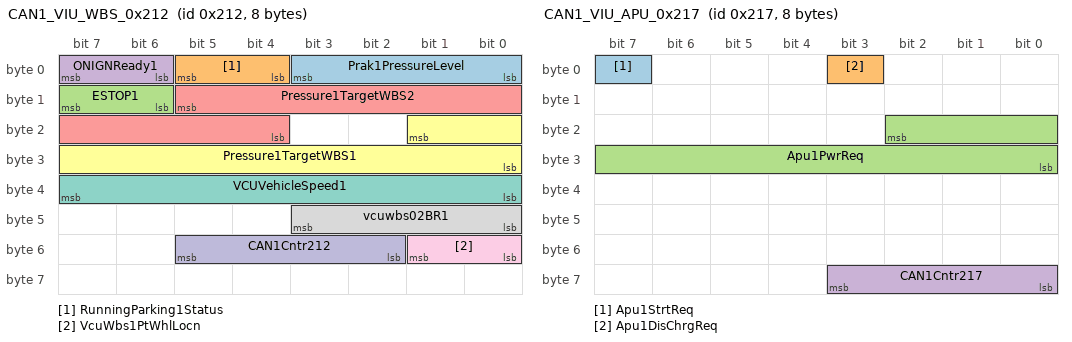
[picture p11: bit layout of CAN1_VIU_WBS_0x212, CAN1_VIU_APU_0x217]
BO_ 530 CAN1_VIU_WBS_0x212: 8 VIU
 SG_ Prak1PressureLevel : 3|4@0+ (1,0) [0|10] "mPa"  WBS
 SG_ RunningParking1Status : 5|2@0+ (1,0) [0|3] ""  WBS
 SG_ ESTOP1 : 15|2@0+ (1,0) [0|3] ""  WBS
 SG_ ONIGNReady1 : 7|2@0+ (1,0) [0|3] ""  WBS
 SG_ Pressure1TargetWBS2 : 13|10@0+ (0.0238,0) [0|10] "mPa"  WBS
 SG_ Pressure1TargetWBS1 : 17|10@0+ (0.0238,0) [0|10] "mPa"  WBS
 SG_ VCUVehicleSpeed1 : 39|8@0+ (1,0) [0|255] "kph"  WBS
 SG_ vcuwbs02BR1 : 43|4@0+ (1,0) [0|15] ""  WBS
 SG_ VcuWbs1PtWhlLocn : 49|2@0+ (1,0) [0|3] ""  WBS
 SG_ CAN1Cntr212 : 53|4@0+ (1,0) [0|15] ""  WBS

BO_ 535 CAN1_VIU_APU_0x217: 8 VIU
 SG_ Apu1StrtReq : 7|1@0+ (1,0) [0|1] ""  APU
 SG_ Apu1DisChrgReq : 3|1@0+ (1,0) [0|1] ""  APU
 SG_ Apu1PwrReq : 18|11@0+ (0.1,-150) [-150|50] "kW"  APU
 SG_ CAN1Cntr217 : 59|4@0+ (1,0) [0|15] ""  APU

BO_ 775 CAN1_VIU_MCU_0x307: 8 VIU
 SG_ VCU1gearposition : 22|3@0+ (1,0) [0|7] ""  MCU

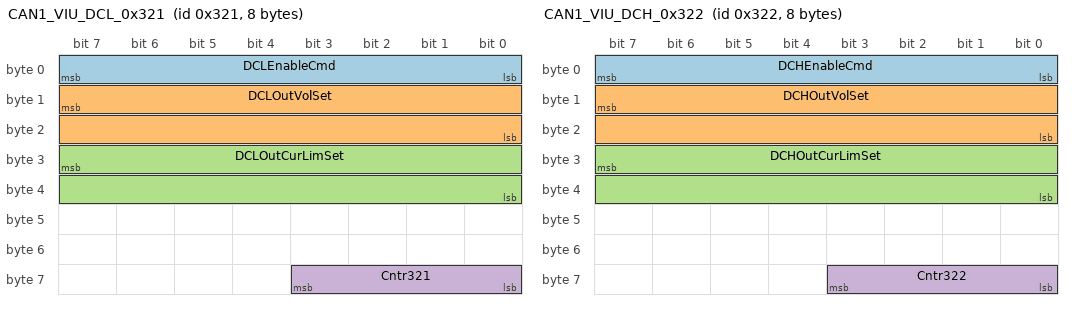
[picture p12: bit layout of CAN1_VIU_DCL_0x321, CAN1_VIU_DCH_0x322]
BO_ 801 CAN1_VIU_DCL_0x321: 8 VIU
 SG_ DCLEnableCmd : 7|8@0+ (1,0) [0|8] ""  DCL
 SG_ DCLOutVolSet : 15|16@0+ (0.1,0) [0|6553.5] "V"  DCL
 SG_ DCLOutCurLimSet : 31|16@0+ (0.1,0) [0|6553.5] "A"  DCL
 SG_ Cntr321 : 59|4@0+ (1,0) [0|15] ""  DCL

BO_ 802 CAN1_VIU_DCH_0x322: 8 VIU
 SG_ DCHEnableCmd : 7|8@0+ (1,0) [0|8] ""  DCH
 SG_ DCHOutVolSet : 15|16@0+ (0.1,0) [0|6553.5] "V"  DCH
 SG_ DCHOutCurLimSet : 31|16@0+ (0.1,0) [0|6553.5] "A"  DCH
 SG_ Cntr322 : 59|4@0+ (1,0) [0|15] ""  DCH

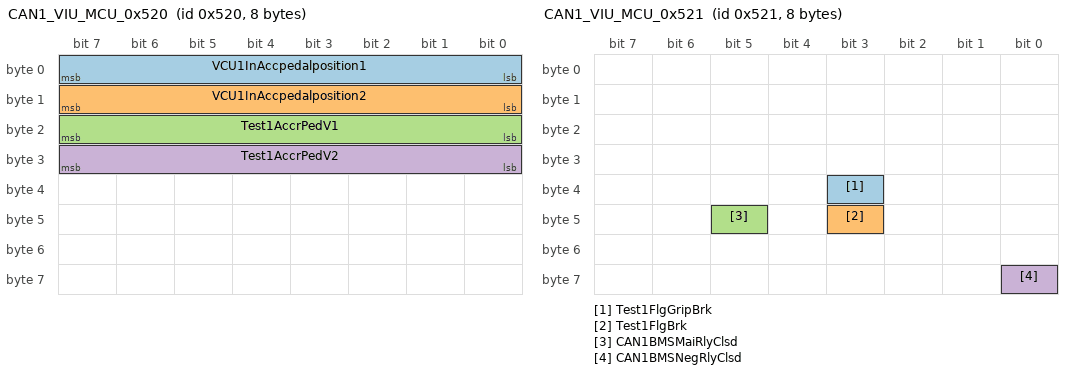
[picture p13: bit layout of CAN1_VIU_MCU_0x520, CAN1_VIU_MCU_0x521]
BO_ 1312 CAN1_VIU_MCU_0x520: 8 VIU
 SG_ VCU1InAccpedalposition1 : 7|8@0+ (0.4,0) [0|100] "%"  MCU
 SG_ VCU1InAccpedalposition2 : 15|8@0+ (0.4,0) [0|100] "%"  MCU
 SG_ Test1AccrPedV1 : 23|8@0+ (0.02,0) [0|5] "V"  MCU
 SG_ Test1AccrPedV2 : 31|8@0+ (0.02,0) [0|5] "V"  MCU

BO_ 1313 CAN1_VIU_MCU_0x521: 8 VIU
 SG_ Test1FlgGripBrk : 35|1@0+ (1,0) [0|1] ""  MCU
 SG_ Test1FlgBrk : 43|1@0+ (1,0) [0|1] ""  MCU
 SG_ CAN1BMSMaiRlyClsd : 45|1@0+ (1,0) [0|1] ""  MCU
 SG_ CAN1BMSNegRlyClsd : 56|1@0+ (1,0) [0|1] ""  MCU

BO_ 513 CAN1_WBS_VIU_0x201: 8 WBS
 SG_ StatusWBS1 : 3|2@0+ (1,0) [0|3] ""  VIU
 SG_ EPBRequest1 : 4|1@0+ (1,0) [0|1] ""  VIU
 SG_ RunParkStatus1 : 7|2@0+ (1,0) [0|3] ""  VIU
 SG_ Wbs1PressureFeedback1 : 1|10@0+ (0.0238,0) [0|10] "Mpa"  VIU
 SG_ WBS1FaultLevel : 20|3@0+ (1,0) [0|7] ""  VIU
 SG_ ParkPressFeedback1 : 23|3@0+ (1,0) [0|7] "mPa"  VIU
 SG_ WBS1BrkCmdAbnormal1 : 32|1@0+ (1,0) [0|1] ""  VIU
 SG_ WBS1PTrackAbnormal1 : 33|1@0+ (1,0) [0|1] ""  VIU
 SG_ PShake1 : 34|1@0+ (1,0) [0|1] ""  VIU
 SG_ WBS1TSnsrFault1 : 35|1@0+ (1,0) [0|1] ""  VIU
 SG_ WBS1TSnsrFault2 : 36|1@0+ (1,0) [0|1] ""  VIU
 SG_ WBS1PSnsrFault2 : 37|1@0+ (1,0) [0|1] ""  VIU
 SG_ WBS1ECUTHigh2 : 38|1@0+ (1,0) [0|1] ""  VIU
 SG_ WBS1VLow2 : 39|1@0+ (1,0) [0|1] ""  VIU
 SG_ WBS1VHigh2 : 40|1@0+ (1,0) [0|1] ""  VIU
 SG_ WBS1PTrackAbnormal2 : 41|1@0+ (1,0) [0|1] ""  VIU
 SG_ WBS1PShake2 : 42|1@0+ (1,0) [0|1] ""  VIU
 SG_ WBS1Mismatch2 : 43|1@0+ (1,0) [0|1] ""  VIU
 SG_ WBS1CANTimeout3 : 44|1@0+ (1,0) [0|1] ""  VIU
 SG_ WBS1OverCurrent4 : 45|1@0+ (1,0) [0|1] ""  VIU
 SG_ WBS1ISnsrAbnormal4 : 46|1@0+ (1,0) [0|1] ""  VIU
 SG_ WBS1VLow4 : 47|1@0+ (1,0) [0|1] ""  VIU
 SG_ WBS1BR : 51|4@0+ (1,0) [0|15] ""  VIU
 SG_ WBS1VHigh4 : 52|1@0+ (1,0) [0|1] ""  VIU
 SG_ WBS1PSwFault4 : 53|1@0+ (1,0) [0|1] ""  VIU
 SG_ WBS1PreDriverFault4 : 54|1@0+ (1,0) [0|1] ""  VIU
 SG_ WBS1MotorPosnSnsrFault4 : 55|1@0+ (1,0) [0|1] ""  VIU
 SG_ CAN1Cntr201 : 63|8@0+ (1,0) [0|15] ""  VIU

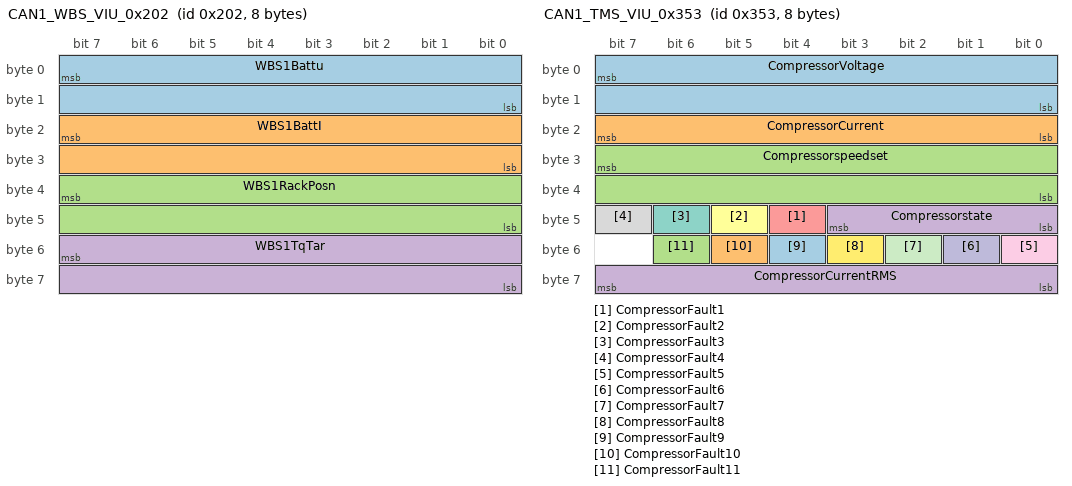
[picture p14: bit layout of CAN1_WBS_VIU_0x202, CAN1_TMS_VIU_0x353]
BO_ 514 CAN1_WBS_VIU_0x202: 8 WBS
 SG_ WBS1Battu : 7|16@0+ (0.25,0) [0|16353.8] "V"  VIU
 SG_ WBS1BattI : 23|16@0- (0.0039063,0) [-128|127.996] "A"  VIU
 SG_ WBS1RackPosn : 39|16@0+ (1,0) [0|65535] "um"  VIU
 SG_ WBS1TqTar : 55|16@0- (0.0039063,0) [-128|127.996] "Nm"  VIU

BO_ 851 CAN1_TMS_VIU_0x353: 8 TMS
 SG_ CompressorVoltage : 7|16@0+ (1,0) [0|1000] "V"  VIU
 SG_ CompressorCurrent : 23|8@0+ (0.1,0) [0|25.5] "A"  VIU
 SG_ Compressorspeedset : 31|16@0+ (1,0) [0|6000] "rpm"  VIU
 SG_ Compressorstate : 43|4@0+ (1,0) [0|15] ""  VIU
 SG_ CompressorFault1 : 44|1@0+ (1,0) [0|1] ""  VIU
 SG_ CompressorFault2 : 45|1@0+ (1,0) [0|1] ""  VIU
 SG_ CompressorFault3 : 46|1@0+ (1,0) [0|1] ""  VIU
 SG_ CompressorFault4 : 47|1@0+ (1,0) [0|1] ""  VIU
 SG_ CompressorFault5 : 48|1@0+ (1,0) [0|1] ""  VIU
 SG_ CompressorFault6 : 49|1@0+ (1,0) [0|1] ""  VIU
 SG_ CompressorFault7 : 50|1@0+ (1,0) [0|1] ""  VIU
 SG_ CompressorFault8 : 51|1@0+ (1,0) [0|1] ""  VIU
 SG_ CompressorFault9 : 52|1@0+ (1,0) [0|1] ""  VIU
 SG_ CompressorFault10 : 53|1@0+ (1,0) [0|1] ""  VIU
 SG_ CompressorFault11 : 54|1@0+ (1,0) [0|1] ""  VIU
 SG_ CompressorCurrentRMS : 63|8@0+ (0.1,0) [0|25.5] "A"  VIU

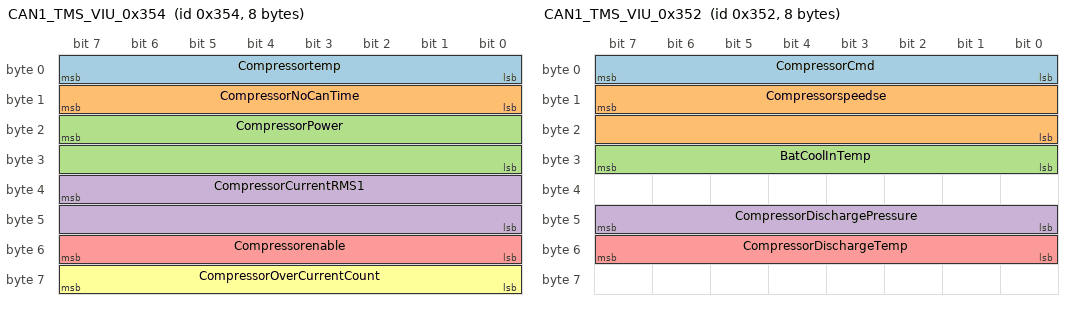
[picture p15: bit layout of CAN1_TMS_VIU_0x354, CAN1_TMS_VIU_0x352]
BO_ 852 CAN1_TMS_VIU_0x354: 8 TMS
 SG_ Compressortemp : 7|8@0+ (1,0) [0|255] "℃"  VIU
 SG_ CompressorNoCanTime : 15|8@0+ (1,0) [0|255] ""  VIU
 SG_ CompressorPower : 23|16@0+ (0.1,0) [0|6553.5] "Kw"  VIU
 SG_ CompressorCurrentRMS1 : 39|16@0+ (1,0) [0|65535] "A"  VIU
 SG_ Compressorenable : 55|8@0+ (1,0) [0|255] ""  VIU
 SG_ CompressorOverCurrentCount : 63|8@0+ (1,0) [0|255] ""  VIU

BO_ 850 CAN1_TMS_VIU_0x352: 8 TMS
 SG_ CompressorCmd : 7|8@0+ (1,0) [0|255] ""  VIU
 SG_ Compressorspeedse : 15|16@0+ (1,0) [0|65535] "rpm"  VIU
 SG_ BatCoolInTemp : 31|8@0+ (1,-40) [-40|200] "℃"  VIU
 SG_ CompressorDischargePressure : 47|8@0+ (0.1,0) [0|25.5] "bar"  VIU
 SG_ CompressorDischargeTemp : 55|8@0+ (1,0) [0|255] "℃"  VIU

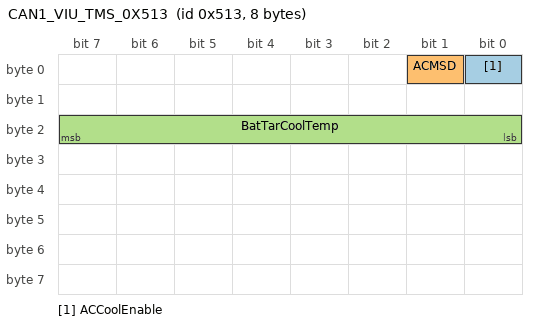
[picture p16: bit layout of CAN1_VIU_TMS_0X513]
BO_ 1299 CAN1_VIU_TMS_0X513: 8 VIU
 SG_ ACCoolEnable : 0|1@0+ (1,0) [0|1] ""  TMS
 SG_ ACMSD : 1|1@0+ (1,0) [0|1] ""  TMS
 SG_ BatTarCoolTemp : 23|8@0+ (1,-40) [-40|200] "℃"  TMS

CM_ SG_ 784 Apu1EngSts "发动机工作状态 
0:等待
1:启动中
2:启动成功
3:运启动故障
4:停机";
CM_ SG_ 784 Apu1ActvEngTorque "飞轮端发动机真实扭矩";
CM_ SG_ 784 Apu1EngCtrlModSts "发动机控制模式 
0:无控制
1:控转速模式
2:控扭矩模式
3:限速限扭模式";
CM_ SG_ 784 Apu1EngSpdActv "发动机转速";
CM_ SG_ 784 Apu1EngOilPressure "发动机轨压";
CM_ SG_ 784 EngpctLoad1 "发动机当前负载率";
CM_ SG_ 784 Ecu1FltRnks "发动机故障等级";
CM_ SG_ 784 Ecu1ErrNo "发动机相关故障代码";
CM_ SG_ 785 Apu1IsgMod "发电机状态 
0:初始化
1:低压上电正常
2:预留
3:电机允许运行
4:电机转速闭环运行
5:电机转矩闭环运行
6:下强电（主动放电）
7:下弱电（高压低于 36V）
8:错误（故障保护）
9: 拖车模式
10:智能下线模式下的准备状态
11: 智能下线模式下的测试状态";
CM_ SG_ 785 Apu1FltRnk "APU故障等级 
0:无故障
1:一级故障
2:二级故障
3:三级故障";
CM_ SG_ 785 Apu1PwrOutp "Apu实际输出功率";
CM_ SG_ 785 Apu1Spd "ISG转速";
CM_ SG_ 785 Apu1CtrlMod "APU控制模式状态 
0:Standy
1:Strt
2:Idle
3:Stop
4:PwrCtrl
5:SpdPwrCtrl";
CM_ SG_ 785 Apu1LimtSpd "ISG限制转速";
CM_ SG_ 785 Apu1ErrNr "APU故障码";
CM_ SG_ 785 Apu1ErrTot "APU故障数";
CM_ SG_ 788 ISG1ElecMotRealTq "ISG电机真实扭矩";
CM_ SG_ 788 ISG1MaxAvlTq "ISG最大可用扭矩";
CM_ SG_ 788 ISG1MinAvlTq "ISG最小可用扭矩";
CM_ SG_ 786 Apu1MotT "电机温度";
CM_ SG_ 786 Apu1McuT "控制器温度";
CM_ SG_ 786 Apu1ACI "ISG交流电流";
CM_ SG_ 786 Apu1DCI "ISG直流电流";
CM_ SG_ 786 Apu1DCU "ISG直流电压";
CM_ SG_ 786 Apu1PwrMaxAllw "APU最大允许输出功率";
CM_ SG_ 787 Apu1ISGPhaCurrHiFault "故障码";
CM_ SG_ 787 Apu1ISGMotSpdHiFault "故障码";
CM_ SG_ 787 Apu1ISGDcLinkVoltHiFault "故障码";
CM_ SG_ 787 Apu1ISGDcLinkVoltLoFault "故障码";
CM_ SG_ 787 Apu1ISGMotBlockFault "故障码";
CM_ SG_ 787 Apu1ISGMcuTempHiFault "故障码";
CM_ SG_ 787 Apu1ISGMotTempHiFault "故障码";
CM_ SG_ 787 Apu1ISGHwFault "故障码";
CM_ SG_ 787 Apu1ISGCmuFault "故障码";
CM_ SG_ 787 Apu1ISGEStopActv "故障码";
CM_ SG_ 787 Apu1ISGErrNr "故障码";
CM_ SG_ 787 Apu1ISGErrTot "故障数量";
CM_ SG_ 787 Apu1ISGFltRank "发电机故障等级";
CM_ SG_ 787 Apu1TqReq "需求扭矩";
CM_ SG_ 787 Apu1SpdReq "发动机转速请求";
CM_ SG_ 1601 Apu1IntakeAirTemp "进气温度T1";
CM_ SG_ 1601 Apu1EngCoolgT "发动机冷却液温度";
CM_ SG_ 1601 Apu1POWERBattU "EMS供电电压";
CM_ SG_ 1601 Apu1AmbientAirPressure "大气压力";
CM_ SG_ 1601 Apu1MaxTorqueAvl "发动机当前允许使用最大扭矩";
CM_ SG_ 1601 Apu1EngFuelCons "发动机的100ms油耗";
CM_ SG_ 1601 APU1EngLubeOilP "发动机机油压力";
CM_ SG_ 385 BCU1MaxDischrgPwrContns "最大持续允许放电功率";
CM_ SG_ 385 BCU1EgyFbAllwdchrgPwrContns "最大持续允许充电功率";
CM_ SG_ 385 BCU1MaxDischrgCur "最大允许持续放电电流";
CM_ SG_ 385 BCU1EgyFbAllwdchrgCur "最大允许持续充电电流";
CM_ SG_ 385 BCU1MinDischrgVol "最小允许放电电压";
CM_ SG_ 385 BCU1EgyFbAllwdchrgVol "最大允许充电电压";
CM_ SG_ 385 BCU1HeatErr "电池加热膜失控故障 
0:无故障
1:有故障";
CM_ SG_ 385 BCU1CycCntr181 "cycle_counter计数";
CM_ SG_ 386 BCU1DcContUSig "直流充电连接确认电压信号";
CM_ SG_ 386 BCU1manufacturerInfo "厂家编号";
CM_ SG_ 386 BCU1pauseChargeFault "充电终止原因 
0:无故障
2:充电桩要求停止充电
3:BMS充电通信类故障
4:整车要求停止充电
6:CC2/CC断开连接停止充电";
CM_ SG_ 386 BCU1Insulated "绝缘电阻";
CM_ SG_ 386 Batt1PwrChrgPeakval10Sec "10S短时峰值充电功率";
CM_ SG_ 386 Batt1PwrDchrgPeakval10Sec "10S短时峰值放电功率";
CM_ SG_ 386 BCU1ErrCode "高压电池故障码";
CM_ SG_ 386 BCU1DCDCBackVol "主正继电器后端电压";
CM_ SG_ 386 BCU1NegRlyClsd "主负继电器状态 
0:Open
1:Close";
CM_ SG_ 387 BCU1BattVol "动力电池总电压";
CM_ SG_ 387 BCU1BattCur "动力电池总电流";
CM_ SG_ 387 BCU1EquiliBrtnNowSt "电池均衡状态 
0:NO
1: YES";
CM_ SG_ 387 BCU1PreRlyClsd "预充电继电器吸合 
0: OFF
1: ON";
CM_ SG_ 387 BCU1MaiRlyClsd "主继电器吸合 
0: OFF
1: ON";
CM_ SG_ 387 BCU1FaultLevel "BCU故障等级 
0:no errors
1:一级故障
2:二级故障
3:三级故障
4:四级故障";
CM_ SG_ 387 BCU1BattSOC "动力电池SOC";
CM_ SG_ 387 BCU1CycCntr183 "cycle_counter计数";
CM_ SG_ 387 BCU1OperMod "Bcu工作模式 
0:Initializing
1:Standby
2:PreCharge
3:HVActive
4:Powerdown
5:Ready to Sleep
15: Failure";
CM_ SG_ 387 BCU1PwrUpAllw "Bcu允许上高压 
0:Not Allow
1:Allow";
CM_ SG_ 387 BCU1ChrgMod "Bcu充电模式 
0:No Charge
1:DC Mode";
CM_ SG_ 387 BCU1ChrgSts "Bcu充电状态 
0:No Charge
1:Charging
2:Charge Full
3:Charge End";
CM_ SG_ 387 BCU1DChrgRlyClsd "直流充电继电器闭合状态 
0:Open
1:Close";
CM_ SG_ 387 BCU1CoolgReq "电池冷却 
0:无需求
1:有冷却需求";
CM_ SG_ 1297 BCU1MaxBattTemp "电池模块最高温度值";
CM_ SG_ 1297 BCU1MinBattTemp "电池模块最低温度值";
CM_ SG_ 1297 BCU1MaxTempModNum "电池最高温度模块对应编号";
CM_ SG_ 1297 BCU1MinTempModNum "电池最低温度模块对应编号";
CM_ SG_ 1297 BCU1AvrgBattTemp "电池平均温度";
CM_ SG_ 1297 BCU1PermMaxBattTemp "允许电池模块最高温度值";
CM_ SG_ 1297 BCU1PermMinBattTemp "允许电池模块最低温度值";
CM_ SG_ 1297 BCU1SOH "电池寿命";
CM_ SG_ 1617 BCU1MaxCellVol "最大单体电压";
CM_ SG_ 1617 BCU1MinCellVol "最小单体电压";
CM_ SG_ 1617 BCU1MaxCellVolNum "最大电压单体对应编号";
CM_ SG_ 1617 BCU1MinCellVolNum "最小电压单体对应编号";
CM_ SG_ 1617 BCU1SOCMax "SOC上限";
CM_ SG_ 1617 BCU1SOCMin "SOC下限";
CM_ SG_ 1618 BCU1CellDeltaVolRank2 "单体电压压差过高二级故障 
0:无故障
1:有故障";
CM_ SG_ 1618 BCU1CellDeltaVolRank1 "单体电压压差过高一级故障 
0:无故障
1:有故障";
CM_ SG_ 1618 BCU1CellUnderVolRank3 "单体电压过低3级故障 
0:无故障
1:有故障";
CM_ SG_ 1618 BCU1CellUnderVolRank2 "单体电压过低2级故障 
0:无故障
1:有故障";
CM_ SG_ 1618 BCU1CellUnderVolRank1 "单体电压过低1级故障 
0:无故障
1:有故障";
CM_ SG_ 1618 BCU1CellOverVolRank3 "单体电压过高3级故障 
0:无故障
1:有故障";
CM_ SG_ 1618 BCU1CellOverVolRank2 "单体电压过高2级故障 
0:无故障
1:有故障";
CM_ SG_ 1618 BCU1CellOverVolRank1 "单体电压过高1级故障 
0:无故障
1:有故障";
CM_ SG_ 1618 BCU1OverCurtChrgRank3 "持续充电电流过高三级故障 
0:无故障
1:有故障";
CM_ SG_ 1618 BCU1OverCurtChrgRank2 "持续充电电流过高二级故障 
0:无故障
1:有故障";
CM_ SG_ 1618 BCU1OverCurtChrgRank1 "持续充电电流过高一级故障 
0:无故障
1:有故障";
CM_ SG_ 1618 BCU1PrechrgFailErr "预充电失败故障(超时) 
0:无故障
1:有故障";
CM_ SG_ 1618 BCU1DCRlyPAdhErr "快充正极继电器粘连 
0:无故障
1:有故障";
CM_ SG_ 1618 BCU1MaiRlyPAdhErr "正极继电器粘连 
0:无故障
1:有故障";
CM_ SG_ 1618 BCU1MaiRlyNAdhErr "负极继电器粘连 
0:无故障
1:有故障";
CM_ SG_ 1618 BCU1CC2Err "CC2检测错误 
0:无故障
1:有故障";
CM_ SG_ 1618 BCU1OverPeakCurtDischrgRank2 "峰值放电电流过高二级故障 
0:无故障
1:有故障";
CM_ SG_ 1618 BCU1OverPeakCurtDischrgRank1 "峰值放电电流过高一级故障 
0:无故障
1:有故障";
CM_ SG_ 1618 BCU1OverCurtDischrgRank3 "持续放电电流过高三级故障 
0:无故障
1:有故障";
CM_ SG_ 1618 BCU1OverCurtDischrgRank2 "持续放电电流过高二级故障 
0:无故障
1:有故障";
CM_ SG_ 1618 BCU1OverCurtDischrgRank1 "持续放电电流过高一级故障 
0:无故障
1:有故障";
CM_ SG_ 1618 BCU1OverPeakCurtChrgRank3 "峰值充电电流过高三级故障 
0:无故障
1:有故障";
CM_ SG_ 1618 BCU1OverPeakCurtChrgRank2 "峰值充电电流过高二级故障 
0:无故障
1:有故障";
CM_ SG_ 1618 BCU1OverPeakCurtChrgRank1 "峰值充电电流过高一级故障 
0:无故障
1:有故障";
CM_ SG_ 1618 BCU1BattUnderTempRank2 "温度过低2级 
0:无故障
1:有故障";
CM_ SG_ 1618 BCU1BattOverTempRank4 "温度过高4级 
0:无故障
1:有故障";
CM_ SG_ 1618 BCU1BattOverTempRank3 "温度过高3级 
0:无故障
1:有故障";
CM_ SG_ 1618 BCU1BattOverTempRank2 "温度过高2级 
0:无故障
1:有故障";
CM_ SG_ 1618 BCU1ChrgErr "充电故障 
0:无故障
1:有故障";
CM_ SG_ 1618 BCU1BattSOHLo "SOC过低故障 
0:无故障
1:有故障";
CM_ SG_ 1618 BCU1TotVolRatiErr "总电压合理性故障:电压采集与电芯累加和差异大 
0:无故障
1:有故障";
CM_ SG_ 1618 BCU1OverPeakCurtDischrgRank3 "峰值放电电流过高三级故障 
0:无故障
1:有故障";
CM_ SG_ 1618 BCU1BattOverURank2 "总电压过高2级 
0:无故障
1:有故障";
CM_ SG_ 1618 BCU1BattOverVolRank1 "总电压过高1级 
0:无故障
1:有故障";
CM_ SG_ 1618 BCU1InsuFlt4 "绝缘故障4级 
0:无故障
1:有故障";
CM_ SG_ 1618 BCU1InsuFlt2 "绝缘故障2级 
0:无故障
1:有故障";
CM_ SG_ 1618 BCU1HVILErr "高压互锁故障 
0:无故障
1:有故障";
CM_ SG_ 1618 BCU1DeltaTempRank3 "温差过大 3级 
0:无故障
1:有故障";
CM_ SG_ 1618 BCU1DeltaTempRank2 "温差过大 2级 
0:无故障
1:有故障";
CM_ SG_ 1618 BCU1BattUnderTempRank3 "温度过低3级 
0:无故障
1:有故障";
CM_ SG_ 1618 BCU1SOCHopErr "SOC跳变故障报警 
0:无故障
1:有故障";
CM_ SG_ 1618 BCU1SOCcalcErr "SOC估算错误 
0:无故障
1:有故障";
CM_ SG_ 1618 BCU1BattOverPwr "超功率故障 
0:无故障
1:有故障";
CM_ SG_ 1618 BCU1DCchrgInsuFlt "充电绝缘故障 
0:无故障
1:有故障";
CM_ SG_ 1618 BCU1BattUnderVolRank3 "总电压过低三级故障 
0:无故障
1:有故障";
CM_ SG_ 1618 BCU1BattUnderVolRank2 "总电压过低二级故障 
0:无故障
1:有故障";
CM_ SG_ 1618 BCU1BattUnderURank1 "总电压过低一级故障 
0:无故障
1:有故障";
CM_ SG_ 1618 BCU1BattOverURank3 "总电压过高3级 
0:无故障
1:有故障";
CM_ SG_ 1618 BCU1TotVolSnsrElecErr "电压传感器检测故障 
0:无故障
1:有故障";
CM_ SG_ 1618 BCU1SlaveCALFAULT "从板标定超出范围故障 
0:无故障
1:有故障";
CM_ SG_ 1618 BCU1InlrCANErr "BCU内网 CAN通讯故障 
0:无故障
1:有故障";
CM_ SG_ 1618 BCU1ChrgCANErr "BCU充电 CAN通讯故障 
0:无故障
1:有故障";
CM_ SG_ 1618 BCU1VehCANErr "BCU整车 CAN通讯故障 
0:无故障
1:有故障";
CM_ SG_ 1618 BCU1BlcErr "均衡故障 
0:无故障
1:有故障";
CM_ SG_ 1618 BCU1ChargerOverTemp3 "充电座过温报警3级 
0:无故障
1:有故障";
CM_ SG_ 1618 BCU1ChargerOverTemp2 "充电座过温报警2级 
0:无故障
1:有故障";
CM_ SG_ 1618 BCU1DCchrgTemErr "DC充电插座温度检测故障 
0:无故障
1:有故障";
CM_ SG_ 1618 BCU1EEpErr "EEPROM 数据错误 
0:无故障
1:有故障";
CM_ SG_ 1618 BCU1WatchDogErr "看门狗相关故障 
0:无故障
1:有故障";
CM_ SG_ 1618 BCU1ROMCheckErr "ROM故障 
0:无故障
1:有故障";
CM_ SG_ 1618 BCU1RAMCheckErr "RAM故障 
0:无故障
1:有故障";
CM_ SG_ 1618 BCU1TempSnsrElecErr "温度传感器故障 
0:无故障
1:有故障";
CM_ SG_ 1618 BCU1TotCurtSnsrElecErr "总电流传感器电气故障 
0:无故障
1:有故障";
CM_ SG_ 1619 BCU1SoftVerx "软件版本_主版本号";
CM_ SG_ 1619 BCU1SoftVeryy "软件版本_次版本号";
CM_ SG_ 1619 BCU1SoftVerzz "软件版本_修订号";
CM_ SG_ 1619 BCU1SoftVeryear "软件版本_年";
CM_ SG_ 1619 BCU1SoftVermonth "软件版本_月";
CM_ SG_ 1619 BCU1SoftVerday "软件版本_日";
CM_ SG_ 1619 BCU1TotalCapacity "总容量";
CM_ SG_ 1539 Dch1Mode "DCDC工作模式24V 
0x0:停止
0x1:运行中
0x2:故障
其他值：预留";
CM_ SG_ 1539 Dch1OutputVol "DCDC输出电压24V";
CM_ SG_ 1539 Dch1OutputCur "DCDC输出电流24V";
CM_ SG_ 1539 Dch1FaultInfo "故障位24V 
位描述：
0:输入欠压
1:输入过压
2:输入过流
3:输出欠压
4:输出过压
5:输出过流
6:模块过温
7:降功率运行
8:通讯故障
9:预留
10:预留
11:预留
12:预留
13:预留
14:预留
15:预留";
CM_ SG_ 1539 CAN1Cntr603 "心跳信号603";
CM_ SG_ 1540 Dch1InputVol "DCDC输入电压24V";
CM_ SG_ 1540 Dch1MaxInterTemp "DCDC内部最高温度24V";
CM_ SG_ 1540 Dch1InputCur "DCDC输入电流24V";
CM_ SG_ 1540 Dch1EnableKL15 "DCDC使能（KL15）24V 
0x0:有效
0x1:无效";
CM_ SG_ 1540 Dch1Version "DCDC版本24V";
CM_ SG_ 1540 Dch1Live "Live24V";
CM_ SG_ 1540 CAN1Cntr604 "心跳信号604";
CM_ SG_ 1537 Dcl1Mode "DCDC工作模式12V 
0x0:停止
0x1:运行中
0x2:故障
0x3：预留";
CM_ SG_ 1537 Dcl1OutputVol "DCDC输出电压12V";
CM_ SG_ 1537 Dcl1OutputCur "DCDC输出电流12V";
CM_ SG_ 1537 Dcl1FaultInfo "故障位12V 
位描述：
0:输入欠压
1:输入过压
2:输入过流
3:输出欠压
4:输出过压
5:输出过流
6:模块过温
7:降功率运行
8:通讯故障
9:预留
10:预留
11:预留
12:预留
13:预留
14:预留
15:预留";
CM_ SG_ 1537 CAN1Cntr601 "心跳信号601";
CM_ SG_ 1538 Dcl1InputVol "DCDC输入电压12V";
CM_ SG_ 1538 Dcl1MaxInterTemp "DCDC内部最高温度12V";
CM_ SG_ 1538 Dcl1InputCur "DCDC输入电流12V";
CM_ SG_ 1538 Dcl1EnableKL15 "DCDC使能（KL15）12V 
0x0:有效
0x1:无效";
CM_ SG_ 1538 Dcl1Version "DCDC版本12V";
CM_ SG_ 1538 Dcl1Live "Live12V";
CM_ SG_ 1538 CAN1Cntr602 "心跳信号602";
CM_ SG_ 339 IPU1ElecMotSpd "电机转速";
CM_ SG_ 339 IPU1ElecMotRealTq "电机真实扭矩";
CM_ SG_ 339 IPU1FactoryMssge "IPU供应商信息 
0x0=曲阜天科;0x1=越博;0x2=依思普林;0x3=汇川";
CM_ SG_ 339 IPU1DischrgSts "电机控制器放电状态 
0x0: 放电未完成;0x1: 放电完成;0x2~0xF:预留信号";
CM_ SG_ 339 Inv1FltRank "IPU故障等级验证 
Note:IPU inv fault rank＋IPU_fault_rank=3   IPUFltRank + InvFltRank两者相加等于三";
CM_ SG_ 339 IPU1FltRank "IPU故障等级 
00:No errors；
01:warning but still working
10:alarm, get into safe mode;
11: stop.  所报故障最高级别，有三级发三，同时有1  2级故障时发二。";
CM_ SG_ 339 IPU1OpenIGBTSts "电机控制器开关管状态 
0x0: Close;0x1: Open;0x2~0xF:预留信号";
CM_ SG_ 339 IPU1ID153CycCntr "cycle counter计数";
CM_ SG_ 339 IPU1RdyForOper "IPU准备进入operation模式 
0x0: No  0x1: Yes";
CM_ SG_ 339 IPU1RdyToShtDwn "IPU准备shutdown 
0x0: No  0x1: Yes";
CM_ SG_ 339 IPU1RdyToPrechrg "允许预充电 
0x0: No  0x1: Yes";
CM_ SG_ 339 IPU1StrtRels "IPU初始化完成 
0x0: No  0x1: Yes";
CM_ SG_ 339 IPU1MaxAvlTq "最大可用扭矩";
CM_ SG_ 339 IPU1MinAvlTq "最小可用扭矩";
CM_ SG_ 371 MCU1DcU "MCU电压";
CM_ SG_ 371 MCU1DcCrrt "MCU电流";
CM_ SG_ 371 MCU1PhaACrrt "A相电流";
CM_ SG_ 371 MCU1PhaBCrrt "B相电流";
CM_ SG_ 371 MCU1ElecMotEff "电机效率";
CM_ SG_ 547 MCU1ElecMotT "电机温度";
CM_ SG_ 547 MCU1IGBTT "逆变器温度";
CM_ SG_ 547 Motor1No "电机数量";
CM_ SG_ 547 MCU1T "MCU温度";
CM_ SG_ 547 MCU1SwVers "软件版本号 
版本号用日期来表示，例如60219表示为2016年2月19日";
CM_ SG_ 547 IPU1ErrNum "故障代码";
CM_ SG_ 547 IPU1ErrAmnt "故障数量";
CM_ SG_ 547 MCU1MotSts "电机状态 
0x0:Reserved
0x1:耗电
0x2:发电
0x3:关闭状态
0x4:准备状态";
CM_ SG_ 1155 CurrentLimitErr1 "逐波限流故障 
0x0：No error；0x1：error";
CM_ SG_ 1155 MCU1IGBTOverTL "IGBT一般过温（模块过温预警） 
0x0：No error；0x1：error";
CM_ SG_ 1155 MCU1IGBTOverTH "IGBT严重过温（模块过温故障） 
0x0：No error；0x1：error";
CM_ SG_ 1155 MCU1ElecMotOverTL "电机一般过温（电机过温预警） 
0x0：No error；0x1：error";
CM_ SG_ 1155 MCU1ElecMotOverTH "电机严重过温（电机过温故障） 
0x0：No error；0x1：error";
CM_ SG_ 1155 MCU1PwrOutpModFlt "功率模块输出故障（硬件驱动故障） 
0x0：No error；0x1：error";
CM_ SG_ 1155 MCU1HardwareOverCurrent "电机硬件过流（硬件过流故障） 
0x0：No error；0x1：error";
CM_ SG_ 1155 MCU1ElecMotOverSpd "电机超速（电机超速故障） 
0x0：No error；0x1：error";
CM_ SG_ 1155 MCU1HiUUnderUL "高压一般欠压 
0x0：No error；0x1：error";
CM_ SG_ 1155 MCU1HiUOverUL "高压一般过压 
0x0：No error；0x1：error";
CM_ SG_ 1155 MCU1CANComErr "CAN通讯错误（CAN离线故障） 
0x0：No error；0x1：error";
CM_ SG_ 1155 MCU1DischrgErr "快放电错误（主动放电故障） 
0x0：No error；0x1：error";
CM_ SG_ 1155 MCU1SoftwareOverCurrent "电机软件过流（软件过流故障） 
0x0：No error；0x1：error";
CM_ SG_ 1155 MCU1ElecMotReslvErr "电机旋变错误（旋变故障） 
0x0：No error；0x1：error";
CM_ SG_ 1155 MCU1ElecMotThreePhaBreakErr "电机三相线缺相 
0x0：No error；0x1：error";
CM_ SG_ 1155 MCU1HiUUnderUH "高压严重欠压（母线欠压故障） 
0x0：No error；0x1：error";
CM_ SG_ 1155 MCU1HiUOverUH "高压严重过压（母线过压故障） 
0x0：No error；0x1：error";
CM_ SG_ 1155 MCU1LowBatErr "低电平欠压（低压欠压故障） 
0x0：No error；0x1：error";
CM_ SG_ 1155 MCU1FAULTDATASELF "数据自检故障 
0x0：No error；0x1：error";
CM_ SG_ 1155 MCU1FAULTUUPIGBT "U相上桥IGBT故障 
0x0：No error；0x1：error";
CM_ SG_ 1155 MCU1FAULTUDOWNIGBT "U相下桥IGBT故障 
0x0：No error；0x1：error";
CM_ SG_ 1155 MCU1FAULTVUPIGBT "V相上桥IGBT故障 
0x0：No error；0x1：error";
CM_ SG_ 1155 MCU1FAULTVDOWNIGBT "V相下桥IGBT故障 
0x0：No error；0x1：error";
CM_ SG_ 1155 MCU1HardwareOverU "MCU硬件过压故障（硬件母线过压故障） 
0x0：No error；0x1：error";
CM_ SG_ 1155 MCU1FAULTWUPIGBT "W相上桥IGBT故障 
0x0：No error；0x1：error";
CM_ SG_ 1155 MCU1FAULTWDOWNIGBT "W相下桥IGBT故障 
0x0：No error；0x1：error";
CM_ SG_ 1155 MCU1LowBatWarning "低压电源欠压预警 
0x0：No error；0x1：error";
CM_ SG_ 1155 MCU1ElecMotOverSpdWarning "电机超速预警 
0x0：No error；0x1：error";
CM_ SG_ 1155 MCU1IGBTTSnsrShoCircGnd "IGBT温度传感器短路接地 
0x0：No error；0x1：error";
CM_ SG_ 1155 MCU1IGBTTSnsrShoCircVcc "IGBT温度传感器短路接电源 
0x0：No error；0x1：error";
CM_ SG_ 1155 MCU1OverLoadErr "控制器过载故障 
0x0：No error；0x1：error";
CM_ SG_ 1155 MCU1OverLoadWraning "控制器过载预警 
0x0：No error；0x1：error";
CM_ SG_ 1155 MCU1ElecMotTSnsrShoCircGnd "电机温度传感器短路接地（电机温度传感器短路故障） 
0x0：No error；0x1：error";
CM_ SG_ 1155 MCU1ElecMotStopTurnErr "电机堵转（堵转预警） 
0x0：No error；0x1：error";
CM_ SG_ 1155 MCU1ElecMotTSnsrOpenCirc "电机温度传感器开路（电机温度传感器断线故障） 
0x0：No error；0x1：error";
CM_ SG_ 1155 MCU1FAULTHUOC "U相硬件过流 
0x0：No error；0x1：error";
CM_ SG_ 1155 MCU1FAULTHVOC "V相硬件过流 
0x0：No error；0x1：error";
CM_ SG_ 1155 MCU1FAULTHWOC "W相硬件过流 
0x0：No error；0x1：error";
CM_ SG_ 1155 MCU1CurrentDetectErr "电路检测故障（交流霍尔自检故障） 
0x0：No error；0x1：error";
CM_ SG_ 1155 MCU1TempErr "控制器水温温差故障 
0x0：No error；0x1：error";
CM_ SG_ 1155 MCU1rDriverUV "EEPROM校验故障 
0x0：No error；0x1：error";
CM_ SG_ 1155 MCU1PhaseShortCircuit "零位差异过大故障 
0x0：No error；0x1：error";
CM_ SG_ 1155 MCU1FastUV "驱动芯片欠压 
0x0：No error；0x1：error";
CM_ SG_ 1155 MCU1alarmOTNTC "相间短路 
0x0：No error；0x1：error";
CM_ SG_ 1155 MCU1OTNTC "快速欠压 
0x0：No error；0x1：error";
CM_ SG_ 1155 MCU1alarmOperateOrder "控制器过温预警 
0x0：No error；0x1：error";
CM_ SG_ 1155 EEPROMErr1 "控制器过温故障 
0x0：No error；0x1：error";
CM_ SG_ 1155 AngleDiffErr1 "操作顺序保护故障 
0x0：No error；0x1：error";
CM_ SG_ 1155 MCU1alarmHighSpeedStop "高速停机保护故障";
CM_ SG_ 1155 MCU1alarmHighSpeedDir "高速误挂挡保护故障";
CM_ SG_ 1155 MCU1alarmHighTorqueStop "大扭矩停机保护 
0x0：No error；0x1：error";
CM_ SG_ 1155 MCU1Dev "速度偏差过大故障 
0x0：No error；0x1：error";
CM_ SG_ 1155 errorCanBSend1 "CAN2发送超时故障 
0x0：No error；0x1：error";
CM_ SG_ 1155 errorCanBReceive1 "CAN2接收超时故障 
0x0：No error；0x1：error";
CM_ SG_ 1155 InterlockErr1 "高压互锁故障 
0x0：No error；0x1：error";
CM_ SG_ 1155 PTCAdhesion1 "PTC继电器粘连故障 
0x0：No error；0x1：error";
CM_ SG_ 1156 MCU1ErrAmnt "故障数量";
CM_ SG_ 1156 MCU1ErrNum1 "故障代码1";
CM_ SG_ 1156 MCU1ErrNum2 "故障代码2";
CM_ SG_ 1156 MCU1ErrNum3 "故障代码3";
CM_ SG_ 1156 MCU1ErrNum4 "故障代码4";
CM_ SG_ 1156 MCU1ErrNum5 "故障代码5";
CM_ SG_ 1156 MCU1ErrNum6 "故障代码6";
CM_ SG_ 1156 MCU1ErrNum7 "故障代码7";
CM_ SG_ 257 PtWhlLocnS "动力轮安装位置 
0:无效
1:左
2:右";
CM_ SG_ 257 PtWhlCompanionBattAvlS "动力电池可用状态 
0:不可用
1:可用";
CM_ SG_ 257 PtWhlTypS "动力轮类型 
0:无效
1:纯电
2:混动";
CM_ SG_ 257 VcuHvActvS "整车高压激活状态 
0:失败
1:成功";
CM_ SG_ 257 VcuLvActvS "整车低压激活状态 
0:失败
1:成功";
CM_ SG_ 257 VcuPwrSysStsNrS "上下电状态机";
CM_ SG_ 257 VCUApuPwrReqS "功率请求";
CM_ SG_ 257 VCUFuQntyS "燃油量";
CM_ SG_ 257 VcuBcuFltRankS "动力电池故障等级 
0:无故障
1:一级故障
2:二级故障
3:三级故障
4:四级故障";
CM_ SG_ 257 BcuCanStS "BcuCan状态 
0:无故障
1:故障";
CM_ SG_ 257 VcuBcuSocS "动力电池Soc";
CM_ SG_ 257 EpbCtrlStsFbS "EPB工作状态 
0:初始化
1:正在夹紧
2:正在释放
3.夹紧完成
4.释放完成
5.夹紧超时
6.释放超时
7.预留
8.预留
9.预留";
CM_ SG_ 257 VcuBcuPwrUpAllwS "Bcu允许上高压 
0:Not Allow
1:Allow";
CM_ SG_ 257 VcuBcuChrgModS "Bcu充电模式 
0:No Charge
1:DC Mode";
CM_ SG_ 257 VcuBcuChrgStsS "Bcu充电状态 
0:No Charge
1:Charging
2:Charge Full
3:Charge End";
CM_ SG_ 257 VcuBcupauseChargeFaultS "充电终止原因 
0:无故障
2:充电桩要求停止充电
3:BMS充电通信类故障
4:整车要求停止充电
6:CC2/CC断开连接停止充电";
CM_ SG_ 257 ErrChrgInhbReqS "禁止充电故障 
0:无故障
1:故障";
CM_ SG_ 257 ErrLvUpInhbS "禁止低压上电故障 
0:无故障
1:故障";
CM_ SG_ 257 ErrLvPwrDwnReqS "低压下电故障 
0:无故障
1:故障";
CM_ SG_ 289 VCU1ElecMotOperMod "电机工作模式 
0x0:No Operation；
0x1:Torque Mode
0x2:Speed Mode;
0x3:Reserved";
CM_ SG_ 289 VCU1SysFltRank "系统故障等级 
0x0:No errors；
0x1:warning
0x2restricted operation;;
0x3:emergency stop";
CM_ SG_ 289 VCU1StrtAllwd "允许MCU开始工作标志位 
0=Invalid; 1=valid";
CM_ SG_ 289 VCU1MCUSpdDischrg "允许MCU激活快速放电标志位 
0=Invalid; 1=valid";
CM_ SG_ 289 VCU1PtWhlLocn "动力轮位置 
0:无效
1:左
2:右";
CM_ SG_ 289 VCU1MCUPwrDwn "整车将进入power_down状态标志位 
0=Invalid; 1=valid";
CM_ SG_ 289 VCU1ReqTq "扭矩请求";
CM_ SG_ 289 VCU1ReqSpd "速度请求";
CM_ SG_ 289 VCU1MaxPermTq "最大允许扭矩";
CM_ SG_ 289 VCU1MinPermTq "最小允许扭矩";
CM_ SG_ 289 VCU1PrecClsInfo "预充电继电器状态 
0x0 : precharge relay is open
0x1 : precharge relay is closed";
CM_ SG_ 289 VCU1MaiRlyClsInfo "主继电器状态 
0x0 : main relay is open
0x1 : main relay is closed";
CM_ SG_ 289 CAN1ID131CycCntr "对扭矩信号进行计数";
CM_ SG_ 305 VCUFltLevel "系统故障等级 
0:No errors
1:warning
2:restricted operation
3:emergency stop";
CM_ SG_ 305 VCUChrgAllw "Vcu允许开始充电 
0:Not Allow
1:Allow";
CM_ SG_ 305 VCUBcuOperModReq "Bcu工作模式请求 
1:Standby
2:HVReq
3:HVActive
4:Powerdown 
5:Sleep";
CM_ SG_ 305 VCUCycCntr "cycle_counter计数";
CM_ SG_ 530 Prak1PressureLevel "驻车压力指令";
CM_ SG_ 530 RunningParking1Status "行驻车指令 
0:驻车
1:行车
2:预留
3:预留";
CM_ SG_ 530 ESTOP1 "紧急制动 
0:正常
1:制动
2:无效
3:无效";
CM_ SG_ 530 ONIGNReady1 "上电/开/就绪";
CM_ SG_ 530 Pressure1TargetWBS2 "WBS2压力指令";
CM_ SG_ 530 Pressure1TargetWBS1 "WBS1压力指令";
CM_ SG_ 530 VCUVehicleSpeed1 "车速";
CM_ SG_ 530 vcuwbs02BR1 "滚动计数器";
CM_ SG_ 530 VcuWbs1PtWhlLocn "动力轮安装位置 
0:无效
1:左
2:右";
CM_ SG_ 530 CAN1Cntr212 "校验值";
CM_ SG_ 535 Apu1StrtReq "发动机起动 
0:停机
1:起动";
CM_ SG_ 535 Apu1DisChrgReq "ISG快放请求 
0:无请求
1:有请求";
CM_ SG_ 535 Apu1PwrReq "功率请求";
CM_ SG_ 535 CAN1Cntr217 "心跳信号217";
CM_ SG_ 775 VCU1gearposition "档位信号 
0x0：N  
0x1：D   
0x2：R   
0x3：E  
0x7：Reserve";
CM_ SG_ 801 DCLEnableCmd "DCDC使能命令12V 
0xAA:启动
0x55:停止";
CM_ SG_ 801 DCLOutVolSet "DCDC输出电压点设置12V";
CM_ SG_ 801 DCLOutCurLimSet "DCDC输出限流点设置12V";
CM_ SG_ 801 Cntr321 "心跳信号321";
CM_ SG_ 802 DCHEnableCmd "DCDC使能命令24V 
0xAA:启动
0x55:停止";
CM_ SG_ 802 DCHOutVolSet "DCDC输出电压点设置24V";
CM_ SG_ 802 DCHOutCurLimSet "DCDC输出限流点设置24V";
CM_ SG_ 802 Cntr322 "心跳信号322";
CM_ SG_ 1312 VCU1InAccpedalposition1 "加速踏板信号1";
CM_ SG_ 1312 VCU1InAccpedalposition2 "加速踏板信号2";
CM_ SG_ 1312 Test1AccrPedV1 "油门踏板电压值1";
CM_ SG_ 1312 Test1AccrPedV2 "油门踏板电压值2";
CM_ SG_ 1313 Test1FlgGripBrk "手刹信号";
CM_ SG_ 1313 Test1FlgBrk "制动踏板被踩下信号";
CM_ SG_ 1313 CAN1BMSMaiRlyClsd "主继电器吸合";
CM_ SG_ 1313 CAN1BMSNegRlyClsd "主负继电器吸合";
CM_ SG_ 513 StatusWBS1 "WBS1状态 
0:未工作
1:正常工作";
CM_ SG_ 513 EPBRequest1 "WBS1驻车请求 
0:无驻车请求
1:请求驻车";
CM_ SG_ 513 RunParkStatus1 "行驻车状态信号 
0:驻车
1:行车
2:急停状态
3:预留";
CM_ SG_ 513 Wbs1PressureFeedback1 "WBS液压力反馈";
CM_ SG_ 513 WBS1FaultLevel "WBS1故障等级 
0:无故障
1:一级故障
2:二级故障
3:三级故障
4:四级故障";
CM_ SG_ 513 ParkPressFeedback1 "前驻车等级反馈";
CM_ SG_ 513 WBS1BrkCmdAbnormal1 "制动指令异常(1) 
0:正常
1:故障";
CM_ SG_ 513 WBS1PTrackAbnormal1 "EHB液压力跟随轻微异常(1) 
0:正常
1:故障";
CM_ SG_ 513 PShake1 "EHB液压力轻微震荡(1) 
0:正常
1:故障";
CM_ SG_ 513 WBS1TSnsrFault1 "温度传感器部分故障(1) 
0:正常
1:故障";
CM_ SG_ 513 WBS1TSnsrFault2 "温度传感器完全故障(2) 
0:正常
1:故障";
CM_ SG_ 513 WBS1PSnsrFault2 "液压力传感器故障(2) 
0:正常
1:故障";
CM_ SG_ 513 WBS1ECUTHigh2 "控制器温度过高(2) 
0:正常
1:故障";
CM_ SG_ 513 WBS1VLow2 "供电电压过低异常(2) 
0:正常
1:故障";
CM_ SG_ 513 WBS1VHigh2 "供电电压过高异常(2) 
0:正常
1:故障";
CM_ SG_ 513 WBS1PTrackAbnormal2 "EHB液压力跟随严重异常(2) 
0:正常
1:故障";
CM_ SG_ 513 WBS1PShake2 "EHB液压力严重震荡(2) 
0:正常
1:故障";
CM_ SG_ 513 WBS1Mismatch2 "负载失配故障(2) 
0:正常
1:故障";
CM_ SG_ 513 WBS1CANTimeout3 "CAN通信故障(3) 
0:正常
1:故障";
CM_ SG_ 513 WBS1OverCurrent4 "EHB过流故障(4) 
0:正常
1:故障";
CM_ SG_ 513 WBS1ISnsrAbnormal4 "电流传感器故障(4) 
0:正常
1:故障";
CM_ SG_ 513 WBS1VLow4 "供电电压过低故障(4) 
0:正常
1:故障";
CM_ SG_ 513 WBS1BR "滚动计数器";
CM_ SG_ 513 WBS1VHigh4 "供电电压过高故障(4) 
0:正常
1:故障";
CM_ SG_ 513 WBS1PSwFault4 "功率开关故障(4) 
0:正常
1:故障";
CM_ SG_ 513 WBS1PreDriverFault4 "预驱故障(4) 
0:正常
1:故障";
CM_ SG_ 513 WBS1MotorPosnSnsrFault4 "EHB电机位置失效(4) 
0:正常
1:故障";
CM_ SG_ 513 CAN1Cntr201 "心跳信号";
CM_ SG_ 514 WBS1Battu "WBS1供电电压";
CM_ SG_ 514 WBS1BattI "WBS1相电流";
CM_ SG_ 514 WBS1RackPosn "WBS1主缸活塞位移";
CM_ SG_ 514 WBS1TqTar "WBS1电机目标力矩";
CM_ SG_ 851 CompressorVoltage "压缩机母线电压";
CM_ SG_ 851 CompressorCurrent "压缩机母线电流";
CM_ SG_ 851 Compressorspeedset "压缩机转速";
CM_ SG_ 851 Compressorstate "压缩机状态 
01：待机（不使能）
02：运行
03：故障停机";
CM_ SG_ 851 CompressorFault1 "欠压；使能指令后小于220V 
0：正常；1故障";
CM_ SG_ 851 CompressorFault2 "过压；大于420V 
0：正常；1故障";
CM_ SG_ 851 CompressorFault3 "母线过流；均值大于16A 
0：正常；1故障";
CM_ SG_ 851 CompressorFault4 "过热；90摄氏度保护（IGBT） 
0：正常；1故障";
CM_ SG_ 851 CompressorFault5 "控制器自检失败：电流传感器检测，温度传感器检测开路或短路 
0：正常；1故障";
CM_ SG_ 851 CompressorFault6 "锁定（连续起动失败10次，不能自恢复） 
0：正常；1故障";
CM_ SG_ 851 CompressorFault7 "相电流过流（RMS）：瞬时30A（60ms）；持续16A（2s） 
0：正常；1故障";
CM_ SG_ 851 CompressorFault8 "通信故障（250个周期） 
0：正常；1故障";
CM_ SG_ 851 CompressorFault9 "预留";
CM_ SG_ 851 CompressorFault10 "预留";
CM_ SG_ 851 CompressorFault11 "预留";
CM_ SG_ 851 CompressorCurrentRMS "压缩机相电流（有效值）";
CM_ SG_ 852 Compressortemp "压缩机温度";
CM_ SG_ 852 CompressorNoCanTime "压缩机无通信计时";
CM_ SG_ 852 CompressorPower "压缩机功率";
CM_ SG_ 852 CompressorCurrentRMS1 "压缩机相电流";
CM_ SG_ 852 Compressorenable "压缩机使能状态反馈";
CM_ SG_ 852 CompressorOverCurrentCount "压缩机过流次数";
CM_ SG_ 850 CompressorCmd "压缩机使能 
0x00:不使能  
0x10:使能";
CM_ SG_ 850 Compressorspeedse "压缩机转速给定(to com)";
CM_ SG_ 850 BatCoolInTemp "电池包入水口温度";
CM_ SG_ 850 CompressorDischargePressure "压缩机排气压力";
CM_ SG_ 850 CompressorDischargeTemp "压缩机排气温度";
CM_ SG_ 1299 ACCoolEnable "冷却开启";
CM_ SG_ 1299 ACMSD "手动维修开关";
CM_ SG_ 1299 BatTarCoolTemp "电池包目标冷却温度";
BA_DEF_ BO_  "GenMsgCycleTime" INT 2 50000;
BA_DEF_ BO_  "CANFD_BRS" ENUM  "0","1";
BA_DEF_  "DBName" STRING ;
BA_DEF_  "BusType" STRING ;
BA_DEF_ BO_  "VFrameFormat" ENUM  "StandardCAN","ExtendedCAN","reserved","reserved","reserved","reserved","reserved","reserved","reserved","reserved","reserved","reserved","reserved","reserved","StandardCAN_FD","ExtendedCAN_FD";
BA_DEF_DEF_  "GenMsgCycleTime" 100;
BA_DEF_DEF_  "CANFD_BRS" "1";
BA_DEF_DEF_  "DBName" "";
BA_DEF_DEF_  "BusType" "";
BA_DEF_DEF_  "VFrameFormat" "StandardCAN";
BA_ "BusType" "CAN FD";
BA_ "DBName" "CAN1";
BA_ "GenMsgCycleTime" BO_ 784 20;
BA_ "GenMsgCycleTime" BO_ 785 20;
BA_ "GenMsgCycleTime" BO_ 788 20;
BA_ "GenMsgCycleTime" BO_ 786 20;
BA_ "GenMsgCycleTime" BO_ 787 20;
BA_ "GenMsgCycleTime" BO_ 1601 200;
BA_ "GenMsgCycleTime" BO_ 385 10;
BA_ "GenMsgCycleTime" BO_ 386 10;
BA_ "GenMsgCycleTime" BO_ 387 10;
BA_ "GenMsgCycleTime" BO_ 1617 1000;
BA_ "GenMsgCycleTime" BO_ 1618 1000;
BA_ "GenMsgCycleTime" BO_ 1619 1000;
BA_ "GenMsgCycleTime" BO_ 1539 500;
BA_ "GenMsgCycleTime" BO_ 1540 500;
BA_ "GenMsgCycleTime" BO_ 1537 500;
BA_ "GenMsgCycleTime" BO_ 1538 500;
BA_ "GenMsgCycleTime" BO_ 339 10;
BA_ "GenMsgCycleTime" BO_ 371 10;
BA_ "GenMsgCycleTime" BO_ 547 1000;
BA_ "GenMsgCycleTime" BO_ 1155 1000;
BA_ "GenMsgCycleTime" BO_ 1156 1000;
BA_ "GenMsgCycleTime" BO_ 257 10;
BA_ "GenMsgCycleTime" BO_ 289 10;
BA_ "GenMsgCycleTime" BO_ 305 10;
BA_ "GenMsgCycleTime" BO_ 530 20;
BA_ "GenMsgCycleTime" BO_ 535 20;
BA_ "GenMsgCycleTime" BO_ 775 10;
BA_ "GenMsgCycleTime" BO_ 801 500;
BA_ "GenMsgCycleTime" BO_ 802 500;
BA_ "GenMsgCycleTime" BO_ 1312 10;
BA_ "GenMsgCycleTime" BO_ 1313 10;
BA_ "GenMsgCycleTime" BO_ 513 20;
BA_ "GenMsgCycleTime" BO_ 514 20;
VAL_ 784 Apu1EngSts 0 "等待" 1 "启动中" 2 "启动成功" 3 "运启动故障" 4 "停机" ;
VAL_ 784 Apu1EngCtrlModSts 0 "无控制" 1 "控转速模式" 2 "控扭矩模式" 3 "限速限扭模式" ;
VAL_ 785 Apu1FltRnk 0 "无故障" 1 "一级故障" 2 "二级故障" 3 "三级故障" ;
VAL_ 785 Apu1CtrlMod 0 "Standy" 1 "Strt" 2 "Idle" 3 "Stop" 4 "PwrCtrl" 5 "SpdPwrCtrl" ;
VAL_ 385 BCU1HeatErr 0 "无故障" 1 "有故障" ;
VAL_ 386 BCU1pauseChargeFault 0 "无故障" 2 "充电桩要求停止充电" 3 "BMS充电通信类故障" 4 "整车要求停止充电" 6 "CC2/CC断开连接停止充电" ;
VAL_ 386 BCU1NegRlyClsd 0 "Open" 1 "Close" ;
VAL_ 387 BCU1DChrgRlyClsd 0 "Open" 1 "Close" ;
VAL_ 387 BCU1CoolgReq 0 "无需求" 1 "有冷却需求" ;
VAL_ 1618 BCU1CellDeltaVolRank2 0 "无故障" 1 "有故障" ;
VAL_ 1618 BCU1CellDeltaVolRank1 0 "无故障" 1 "有故障" ;
VAL_ 1618 BCU1CellUnderVolRank3 0 "无故障" 1 "有故障" ;
VAL_ 1618 BCU1CellUnderVolRank2 0 "无故障" 1 "有故障" ;
VAL_ 1618 BCU1CellUnderVolRank1 0 "无故障" 1 "有故障" ;
VAL_ 1618 BCU1CellOverVolRank3 0 "无故障" 1 "有故障" ;
VAL_ 1618 BCU1CellOverVolRank2 0 "无故障" 1 "有故障" ;
VAL_ 1618 BCU1CellOverVolRank1 0 "无故障" 1 "有故障" ;
VAL_ 1618 BCU1OverCurtChrgRank3 0 "无故障" 1 "有故障" ;
VAL_ 1618 BCU1OverCurtChrgRank2 0 "无故障" 1 "有故障" ;
VAL_ 1618 BCU1OverCurtChrgRank1 0 "无故障" 1 "有故障" ;
VAL_ 1618 BCU1PrechrgFailErr 0 "无故障" 1 "有故障" ;
VAL_ 1618 BCU1DCRlyPAdhErr 0 "无故障" 1 "有故障" ;
VAL_ 1618 BCU1MaiRlyPAdhErr 0 "无故障" 1 "有故障" ;
VAL_ 1618 BCU1MaiRlyNAdhErr 0 "无故障" 1 "有故障" ;
VAL_ 1618 BCU1CC2Err 0 "无故障" 1 "有故障" ;
VAL_ 1618 BCU1OverPeakCurtDischrgRank2 0 "无故障" 1 "有故障" ;
VAL_ 1618 BCU1OverPeakCurtDischrgRank1 0 "无故障" 1 "有故障" ;
VAL_ 1618 BCU1OverCurtDischrgRank3 0 "无故障" 1 "有故障" ;
VAL_ 1618 BCU1OverCurtDischrgRank2 0 "无故障" 1 "有故障" ;
VAL_ 1618 BCU1OverCurtDischrgRank1 0 "无故障" 1 "有故障" ;
VAL_ 1618 BCU1OverPeakCurtChrgRank3 0 "无故障" 1 "有故障" ;
VAL_ 1618 BCU1OverPeakCurtChrgRank2 0 "无故障" 1 "有故障" ;
VAL_ 1618 BCU1OverPeakCurtChrgRank1 0 "无故障" 1 "有故障" ;
VAL_ 1618 BCU1BattUnderTempRank2 0 "无故障" 1 "有故障" ;
VAL_ 1618 BCU1BattOverTempRank4 0 "无故障" 1 "有故障" ;
VAL_ 1618 BCU1BattOverTempRank3 0 "无故障" 1 "有故障" ;
VAL_ 1618 BCU1BattOverTempRank2 0 "无故障" 1 "有故障" ;
VAL_ 1618 BCU1ChrgErr 0 "无故障" 1 "有故障" ;
VAL_ 1618 BCU1BattSOHLo 0 "无故障" 1 "有故障" ;
VAL_ 1618 BCU1TotVolRatiErr 0 "无故障" 1 "有故障" ;
VAL_ 1618 BCU1OverPeakCurtDischrgRank3 0 "无故障" 1 "有故障" ;
VAL_ 1618 BCU1BattOverURank2 0 "无故障" 1 "有故障" ;
VAL_ 1618 BCU1BattOverVolRank1 0 "无故障" 1 "有故障" ;
VAL_ 1618 BCU1InsuFlt4 0 "无故障" 1 "有故障" ;
VAL_ 1618 BCU1InsuFlt2 0 "无故障" 1 "有故障" ;
VAL_ 1618 BCU1HVILErr 0 "无故障" 1 "有故障" ;
VAL_ 1618 BCU1DeltaTempRank3 0 "无故障" 1 "有故障" ;
VAL_ 1618 BCU1DeltaTempRank2 0 "无故障" 1 "有故障" ;
VAL_ 1618 BCU1BattUnderTempRank3 0 "无故障" 1 "有故障" ;
VAL_ 1618 BCU1SOCHopErr 0 "无故障" 1 "有故障" ;
VAL_ 1618 BCU1SOCcalcErr 0 "无故障" 1 "有故障" ;
VAL_ 1618 BCU1BattOverPwr 0 "无故障" 1 "有故障" ;
VAL_ 1618 BCU1DCchrgInsuFlt 0 "无故障" 1 "有故障" ;
VAL_ 1618 BCU1BattUnderVolRank3 0 "无故障" 1 "有故障" ;
VAL_ 1618 BCU1BattUnderVolRank2 0 "无故障" 1 "有故障" ;
VAL_ 1618 BCU1BattUnderURank1 0 "无故障" 1 "有故障" ;
VAL_ 1618 BCU1BattOverURank3 0 "无故障" 1 "有故障" ;
VAL_ 1618 BCU1TotVolSnsrElecErr 0 "无故障" 1 "有故障" ;
VAL_ 1618 BCU1SlaveCALFAULT 0 "无故障" 1 "有故障" ;
VAL_ 1618 BCU1InlrCANErr 0 "无故障" 1 "有故障" ;
VAL_ 1618 BCU1ChrgCANErr 0 "无故障" 1 "有故障" ;
VAL_ 1618 BCU1VehCANErr 0 "无故障" 1 "有故障" ;
VAL_ 1618 BCU1BlcErr 0 "无故障" 1 "有故障" ;
VAL_ 1618 BCU1ChargerOverTemp3 0 "无故障" 1 "有故障" ;
VAL_ 1618 BCU1ChargerOverTemp2 0 "无故障" 1 "有故障" ;
VAL_ 1618 BCU1DCchrgTemErr 0 "无故障" 1 "有故障" ;
VAL_ 1618 BCU1EEpErr 0 "无故障" 1 "有故障" ;
VAL_ 1618 BCU1WatchDogErr 0 "无故障" 1 "有故障" ;
VAL_ 1618 BCU1ROMCheckErr 0 "无故障" 1 "有故障" ;
VAL_ 1618 BCU1RAMCheckErr 0 "无故障" 1 "有故障" ;
VAL_ 1618 BCU1TempSnsrElecErr 0 "无故障" 1 "有故障" ;
VAL_ 1618 BCU1TotCurtSnsrElecErr 0 "无故障" 1 "有故障" ;
VAL_ 1539 Dch1Mode 0 "停止" 1 "运行中" 2 "故障" ;
VAL_ 1539 Dch1FaultInfo 0 "输入欠压" 1 "输入过压" 2 "输入过流" 3 "输出欠压" 4 "输出过压" 5 "输出过流" 6 "模块过温" 7 "降功率运行" 8 "通讯故障" 9 "预留" 10 "预留" 11 "预留" 12 "预留" 13 "预留" 14 "预留" 15 "预留" ;
VAL_ 1540 Dch1EnableKL15 0 "有效" 1 "无效" ;
VAL_ 1537 Dcl1Mode 0 "停止" 1 "运行中" 2 "故障" ;
VAL_ 1537 Dcl1FaultInfo 0 "输入欠压" 1 "输入过压" 2 "输入过流" 3 "输出欠压" 4 "输出过压" 5 "输出过流" 6 "模块过温" 7 "降功率运行" 8 "通讯故障" 9 "预留" 10 "预留" 11 "预留" 12 "预留" 13 "预留" 14 "预留" 15 "预留" ;
VAL_ 1538 Dcl1EnableKL15 0 "有效" 1 "无效" ;
VAL_ 547 MCU1MotSts 0 "Reserved" 1 "耗电" 2 "发电" 3 "关闭状态" 4 "准备状态" ;
VAL_ 257 PtWhlLocnS 0 "无效" 1 "左" 2 "右" ;
VAL_ 257 PtWhlCompanionBattAvlS 0 "不可用" 1 "可用" ;
VAL_ 257 PtWhlTypS 0 "无效" 1 "纯电" 2 "混动" ;
VAL_ 257 VcuHvActvS 0 "失败" 1 "成功" ;
VAL_ 257 VcuLvActvS 0 "失败" 1 "成功" ;
VAL_ 257 VcuBcuFltRankS 0 "无故障" 1 "一级故障" 2 "二级故障" 3 "三级故障" 4 "四级故障" ;
VAL_ 257 BcuCanStS 0 "无故障" 1 "故障" ;
VAL_ 257 EpbCtrlStsFbS 0 "初始化" 1 "正在夹紧" 2 "正在释放" ;
VAL_ 257 VcuBcupauseChargeFaultS 0 "无故障" 2 "充电桩要求停止充电" 3 "BMS充电通信类故障" 4 "整车要求停止充电" 6 "CC2/CC断开连接停止充电" ;
VAL_ 257 ErrChrgInhbReqS 0 "无故障" 1 "故障" ;
VAL_ 257 ErrLvUpInhbS 0 "无故障" 1 "故障" ;
VAL_ 257 ErrLvPwrDwnReqS 0 "无故障" 1 "故障" ;
VAL_ 289 VCU1PtWhlLocn 0 "无效" 1 "左" 2 "右" ;
VAL_ 530 RunningParking1Status 0 "驻车" 1 "行车" 2 "预留" 3 "预留" ;
VAL_ 530 ESTOP1 0 "正常" 1 "制动" 2 "无效" 3 "无效" ;
VAL_ 530 VcuWbs1PtWhlLocn 0 "无效" 1 "左" 2 "右" ;
VAL_ 535 Apu1StrtReq 0 "停机" 1 "起动" ;
VAL_ 535 Apu1DisChrgReq 0 "无请求" 1 "有请求" ;
VAL_ 801 DCLEnableCmd 170 "启动" 85 "停止" ;
VAL_ 802 DCHEnableCmd 170 "启动" 85 "停止" ;
VAL_ 513 StatusWBS1 0 "未工作" 1 "正常工作" ;
VAL_ 513 EPBRequest1 0 "无驻车请求" 1 "请求驻车" ;
VAL_ 513 RunParkStatus1 0 "驻车" 1 "行车" 2 "急停状态" 3 "预留" ;
VAL_ 513 WBS1FaultLevel 0 "无故障" 1 "一级故障" 2 "二级故障" 3 "三级故障" 4 "四级故障" ;
VAL_ 513 WBS1BrkCmdAbnormal1 0 "正常" 1 "故障" ;
VAL_ 513 WBS1PTrackAbnormal1 0 "正常" 1 "故障" ;
VAL_ 513 PShake1 0 "正常" 1 "故障" ;
VAL_ 513 WBS1TSnsrFault1 0 "正常" 1 "故障" ;
VAL_ 513 WBS1TSnsrFault2 0 "正常" 1 "故障" ;
VAL_ 513 WBS1PSnsrFault2 0 "正常" 1 "故障" ;
VAL_ 513 WBS1ECUTHigh2 0 "正常" 1 "故障" ;
VAL_ 513 WBS1VLow2 0 "正常" 1 "故障" ;
VAL_ 513 WBS1VHigh2 0 "正常" 1 "故障" ;
VAL_ 513 WBS1PTrackAbnormal2 0 "正常" 1 "故障" ;
VAL_ 513 WBS1PShake2 0 "正常" 1 "故障" ;
VAL_ 513 WBS1Mismatch2 0 "正常" 1 "故障" ;
VAL_ 513 WBS1CANTimeout3 0 "正常" 1 "故障" ;
VAL_ 513 WBS1OverCurrent4 0 "正常" 1 "故障" ;
VAL_ 513 WBS1ISnsrAbnormal4 0 "正常" 1 "故障" ;
VAL_ 513 WBS1VLow4 0 "正常" 1 "故障" ;
VAL_ 513 WBS1VHigh4 0 "正常" 1 "故障" ;
VAL_ 513 WBS1PSwFault4 0 "正常" 1 "故障" ;
VAL_ 513 WBS1PreDriverFault4 0 "正常" 1 "故障" ;
VAL_ 513 WBS1MotorPosnSnsrFault4 0 "正常" 1 "故障" ;
